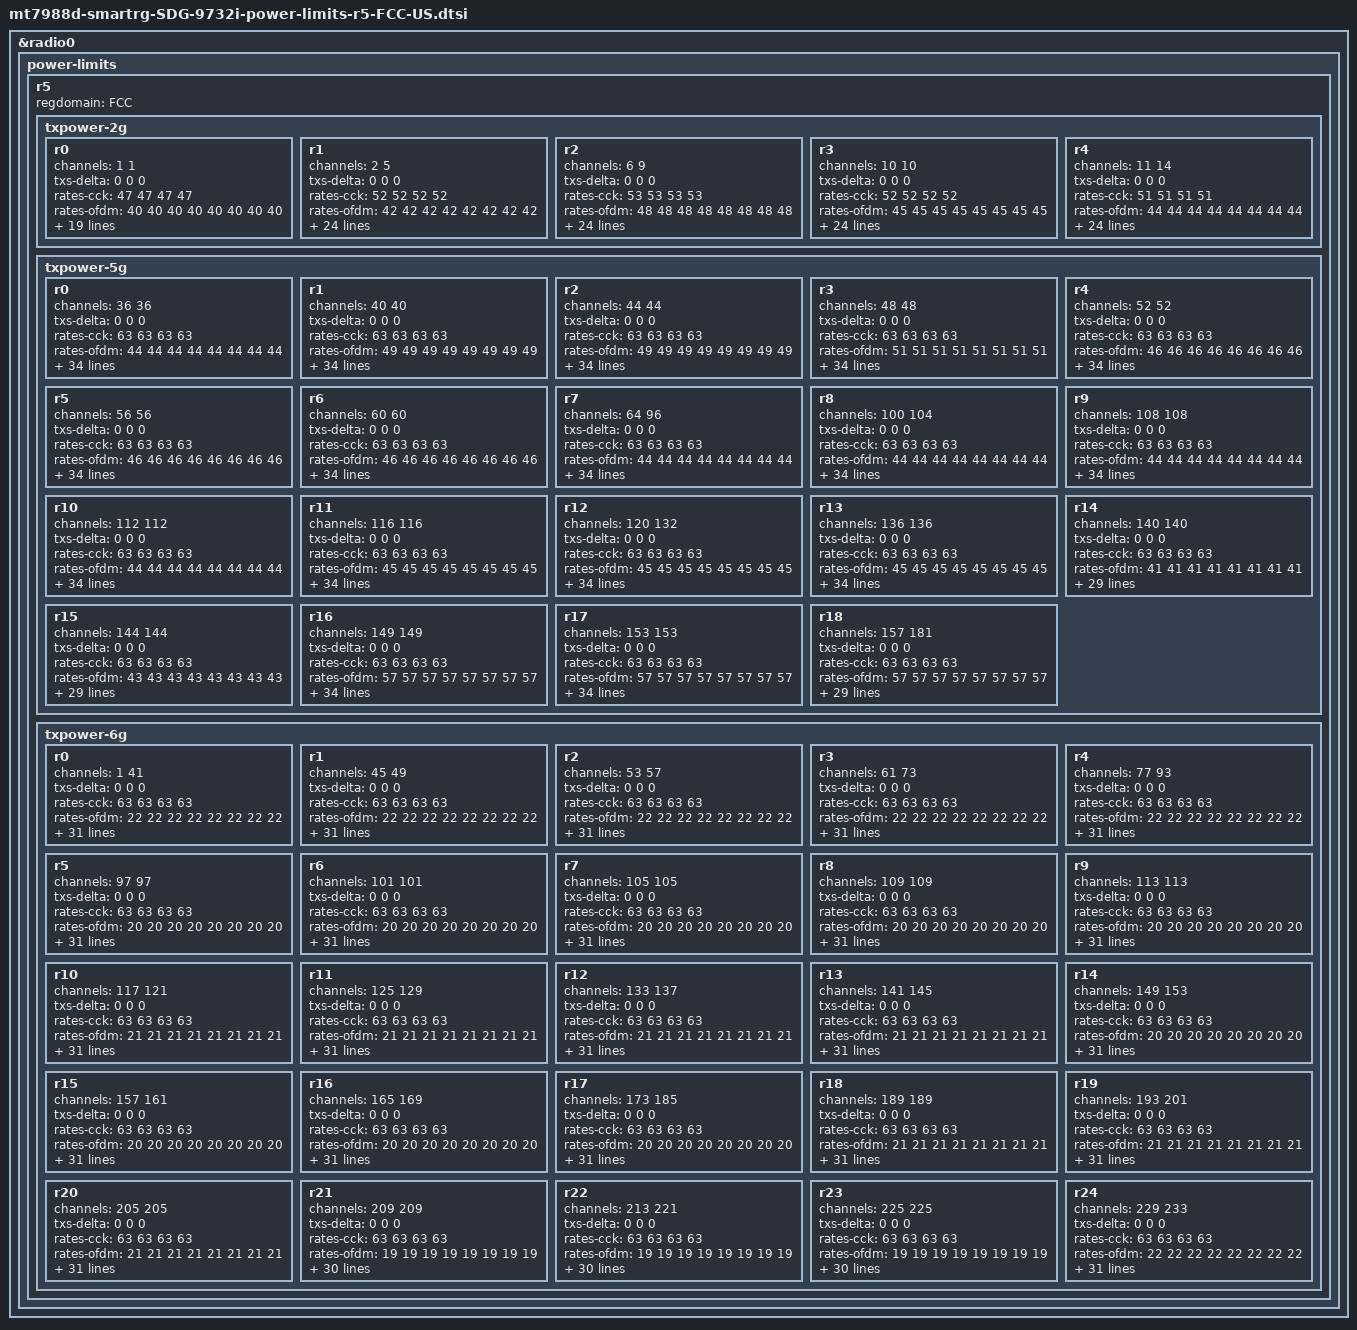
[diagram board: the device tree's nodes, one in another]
// SPDX-License-Identifier: (GPL-2.0 OR MIT)
/*
 * Copyright (C) 2024 SmartRG Inc.
 * Author: Chad Monroe <chad.monroe@smartrg.com>
 */

&radio0 {
	power-limits {
		r5 {
			regdomain = "FCC";

			txpower-2g {
				r0 {
					channels = <1 1>;
					txs-delta = <0 0 0>;
					rates-cck = /bits/ 8 <47 47 47 47>;
					rates-ofdm = /bits/ 8 <40 40 40 40 40 40 40 40>;
					rates-mcs =
					/bits/ 8 <2 39 39 39 39 39 39 39 39 39 39>,
					/bits/ 8 <2 63 63 63 63 63 63 63 63 63 63>;
					rates-ru =
					/bits/ 8 <5 39 39 39 39 39 39 39 39 39 39 39 39>,
					/bits/ 8 <2 63 63 63 63 63 63 63 63 63 63 63 63>;
					rates-eht =
					/bits/ 8 <5 39 39 39 39 39 39 39 39 39 39 39 39 39 39 39 39>,
					/bits/ 8 <3 63 63 63 63 63 63 63 63 63 63 63 63 63 63 63 63>,
					/bits/ 8 <2 39 39 39 39 39 39 39 39 39 39 39 39 39 39 39 39>,
					/bits/ 8 <6 63 63 63 63 63 63 63 63 63 63 63 63 63 63 63 63>;
					paths-cck = /bits/ 8 <47 41 37 35 33>;
					paths-ofdm = /bits/ 8 <40 34 30 28 26>;
					paths-ofdm-bf = /bits/ 8 <28 21 16 12>;
					paths-ru =
					/bits/ 8 <7 39 33 29 27 25 33 29 27 25 29 27 25 27 25 25>,
					/bits/ 8 <9 63 63 63 63 63 63 63 63 63 63 63 63 63 63 63>;
					paths-ru-bf =
					/bits/ 8 <7 39 27 20 15 11 33 26 21 17 29 24 21 27 23 25>,
					/bits/ 8 <9 63 63 63 63 63 63 63 63 63 63 63 63 63 63 63>;
				};
				r1 {
					channels = <2 5>;
					txs-delta = <0 0 0>;
					rates-cck = /bits/ 8 <52 52 52 52>;
					rates-ofdm = /bits/ 8 <42 42 42 42 42 42 42 42>;
					rates-mcs =
					/bits/ 8 <1 42 42 42 42 42 42 42 42 42 42>,
					/bits/ 8 <1 39 39 39 39 39 39 39 39 39 39>,
					/bits/ 8 <2 63 63 63 63 63 63 63 63 63 63>;
					rates-ru =
					/bits/ 8 <4 42 42 42 42 42 42 42 42 42 42 42 42>,
					/bits/ 8 <1 39 39 39 39 39 39 39 39 39 39 39 39>,
					/bits/ 8 <2 63 63 63 63 63 63 63 63 63 63 63 63>;
					rates-eht =
					/bits/ 8 <4 42 42 42 42 42 42 42 42 42 42 42 42 42 42 42 42>,
					/bits/ 8 <1 39 39 39 39 39 39 39 39 39 39 39 39 39 39 39 39>,
					/bits/ 8 <3 63 63 63 63 63 63 63 63 63 63 63 63 63 63 63 63>,
					/bits/ 8 <2 42 42 42 42 42 42 42 42 42 42 42 42 42 42 42 42>,
					/bits/ 8 <6 63 63 63 63 63 63 63 63 63 63 63 63 63 63 63 63>;
					paths-cck = /bits/ 8 <52 46 42 40 38>;
					paths-ofdm = /bits/ 8 <42 36 32 30 28>;
					paths-ofdm-bf = /bits/ 8 <30 23 18 14>;
					paths-ru =
					/bits/ 8 <6 42 36 32 30 28 36 32 30 28 32 30 28 30 28 28>,
					/bits/ 8 <1 39 33 29 27 25 33 29 27 25 29 27 25 27 25 25>,
					/bits/ 8 <9 63 63 63 63 63 63 63 63 63 63 63 63 63 63 63>;
					paths-ru-bf =
					/bits/ 8 <6 42 30 23 18 14 36 29 24 20 32 27 24 30 26 28>,
					/bits/ 8 <1 39 27 20 15 11 33 26 21 17 29 24 21 27 23 25>,
					/bits/ 8 <9 63 63 63 63 63 63 63 63 63 63 63 63 63 63 63>;
				};
				r2 {
					channels = <6 9>;
					txs-delta = <0 0 0>;
					rates-cck = /bits/ 8 <53 53 53 53>;
					rates-ofdm = /bits/ 8 <48 48 48 48 48 48 48 48>;
					rates-mcs =
					/bits/ 8 <1 46 46 46 46 46 46 46 46 46 46>,
					/bits/ 8 <1 41 41 41 41 41 41 41 41 41 41>,
					/bits/ 8 <2 63 63 63 63 63 63 63 63 63 63>;
					rates-ru =
					/bits/ 8 <4 46 46 46 46 46 46 46 46 46 46 46 46>,
					/bits/ 8 <1 41 41 41 41 41 41 41 41 41 41 41 41>,
					/bits/ 8 <2 63 63 63 63 63 63 63 63 63 63 63 63>;
					rates-eht =
					/bits/ 8 <4 46 46 46 46 46 46 46 46 46 46 46 46 46 46 46 46>,
					/bits/ 8 <1 41 41 41 41 41 41 41 41 41 41 41 41 41 41 41 41>,
					/bits/ 8 <3 63 63 63 63 63 63 63 63 63 63 63 63 63 63 63 63>,
					/bits/ 8 <2 46 46 46 46 46 46 46 46 46 46 46 46 46 46 46 46>,
					/bits/ 8 <6 63 63 63 63 63 63 63 63 63 63 63 63 63 63 63 63>;
					paths-cck = /bits/ 8 <53 47 43 41 39>;
					paths-ofdm = /bits/ 8 <48 42 38 36 34>;
					paths-ofdm-bf = /bits/ 8 <36 29 24 20>;
					paths-ru =
					/bits/ 8 <6 46 40 36 34 32 40 36 34 32 36 34 32 34 32 32>,
					/bits/ 8 <1 41 35 31 29 27 35 31 29 27 31 29 27 29 27 27>,
					/bits/ 8 <9 63 63 63 63 63 63 63 63 63 63 63 63 63 63 63>;
					paths-ru-bf =
					/bits/ 8 <6 46 34 27 22 18 40 33 28 24 36 31 28 34 30 32>,
					/bits/ 8 <1 41 29 22 17 13 35 28 23 19 31 26 23 29 25 27>,
					/bits/ 8 <9 63 63 63 63 63 63 63 63 63 63 63 63 63 63 63>;
				};
				r3 {
					channels = <10 10>;
					txs-delta = <0 0 0>;
					rates-cck = /bits/ 8 <52 52 52 52>;
					rates-ofdm = /bits/ 8 <45 45 45 45 45 45 45 45>;
					rates-mcs =
					/bits/ 8 <1 44 44 44 44 44 44 44 44 44 44>,
					/bits/ 8 <1 41 41 41 41 41 41 41 41 41 41>,
					/bits/ 8 <2 63 63 63 63 63 63 63 63 63 63>;
					rates-ru =
					/bits/ 8 <4 44 44 44 44 44 44 44 44 44 44 44 44>,
					/bits/ 8 <1 41 41 41 41 41 41 41 41 41 41 41 41>,
					/bits/ 8 <2 63 63 63 63 63 63 63 63 63 63 63 63>;
					rates-eht =
					/bits/ 8 <4 44 44 44 44 44 44 44 44 44 44 44 44 44 44 44 44>,
					/bits/ 8 <1 41 41 41 41 41 41 41 41 41 41 41 41 41 41 41 41>,
					/bits/ 8 <3 63 63 63 63 63 63 63 63 63 63 63 63 63 63 63 63>,
					/bits/ 8 <2 44 44 44 44 44 44 44 44 44 44 44 44 44 44 44 44>,
					/bits/ 8 <6 63 63 63 63 63 63 63 63 63 63 63 63 63 63 63 63>;
					paths-cck = /bits/ 8 <52 46 42 40 38>;
					paths-ofdm = /bits/ 8 <45 39 35 33 31>;
					paths-ofdm-bf = /bits/ 8 <33 26 21 17>;
					paths-ru =
					/bits/ 8 <6 44 38 34 32 30 38 34 32 30 34 32 30 32 30 30>,
					/bits/ 8 <1 41 35 31 29 27 35 31 29 27 31 29 27 29 27 27>,
					/bits/ 8 <9 63 63 63 63 63 63 63 63 63 63 63 63 63 63 63>;
					paths-ru-bf =
					/bits/ 8 <6 44 32 25 20 16 38 31 26 22 34 29 26 32 28 30>,
					/bits/ 8 <1 41 29 22 17 13 35 28 23 19 31 26 23 29 25 27>,
					/bits/ 8 <9 63 63 63 63 63 63 63 63 63 63 63 63 63 63 63>;
				};
				r4 {
					channels = <11 14>;
					txs-delta = <0 0 0>;
					rates-cck = /bits/ 8 <51 51 51 51>;
					rates-ofdm = /bits/ 8 <44 44 44 44 44 44 44 44>;
					rates-mcs =
					/bits/ 8 <1 42 42 42 42 42 42 42 42 42 42>,
					/bits/ 8 <1 41 41 41 41 41 41 41 41 41 41>,
					/bits/ 8 <2 63 63 63 63 63 63 63 63 63 63>;
					rates-ru =
					/bits/ 8 <4 42 42 42 42 42 42 42 42 42 42 42 42>,
					/bits/ 8 <1 41 41 41 41 41 41 41 41 41 41 41 41>,
					/bits/ 8 <2 63 63 63 63 63 63 63 63 63 63 63 63>;
					rates-eht =
					/bits/ 8 <4 42 42 42 42 42 42 42 42 42 42 42 42 42 42 42 42>,
					/bits/ 8 <1 41 41 41 41 41 41 41 41 41 41 41 41 41 41 41 41>,
					/bits/ 8 <3 63 63 63 63 63 63 63 63 63 63 63 63 63 63 63 63>,
					/bits/ 8 <2 42 42 42 42 42 42 42 42 42 42 42 42 42 42 42 42>,
					/bits/ 8 <6 63 63 63 63 63 63 63 63 63 63 63 63 63 63 63 63>;
					paths-cck = /bits/ 8 <51 45 41 39 37>;
					paths-ofdm = /bits/ 8 <44 38 34 32 30>;
					paths-ofdm-bf = /bits/ 8 <32 25 20 16>;
					paths-ru =
					/bits/ 8 <6 42 36 32 30 28 36 32 30 28 32 30 28 30 28 28>,
					/bits/ 8 <1 41 35 31 29 27 35 31 29 27 31 29 27 29 27 27>,
					/bits/ 8 <9 63 63 63 63 63 63 63 63 63 63 63 63 63 63 63>;
					paths-ru-bf =
					/bits/ 8 <6 42 30 23 18 14 36 29 24 20 32 27 24 30 26 28>,
					/bits/ 8 <1 41 29 22 17 13 35 28 23 19 31 26 23 29 25 27>,
					/bits/ 8 <9 63 63 63 63 63 63 63 63 63 63 63 63 63 63 63>;
				};
			};
			txpower-5g {
				r0 {
					channels = <36 36>;
					txs-delta = <0 0 0>;
					rates-cck = /bits/ 8 <63 63 63 63>;
					rates-ofdm = /bits/ 8 <44 44 44 44 44 44 44 44>;
					rates-mcs =
					/bits/ 8 <1 42 42 42 42 42 42 42 42 42 42>,
					/bits/ 8 <1 38 38 38 38 38 38 38 38 38 38>,
					/bits/ 8 <1 32 32 32 32 32 32 32 32 32 32>,
					/bits/ 8 <1 28 28 28 28 28 28 28 28 28 28>;
					rates-ru =
					/bits/ 8 <4 42 42 42 42 42 42 42 42 42 42 42 42>,
					/bits/ 8 <1 38 38 38 38 38 38 38 38 38 38 38 38>,
					/bits/ 8 <1 32 32 32 32 32 32 32 32 32 32 32 32>,
					/bits/ 8 <1 28 28 28 28 28 28 28 28 28 28 28 28>;
					rates-eht =
					/bits/ 8 <4 42 42 42 42 42 42 42 42 42 42 42 42 42 42 42 42>,
					/bits/ 8 <1 38 38 38 38 38 38 38 38 38 38 38 38 38 38 38 38>,
					/bits/ 8 <1 32 32 32 32 32 32 32 32 32 32 32 32 32 32 32 32>,
					/bits/ 8 <1 28 28 28 28 28 28 28 28 28 28 28 28 28 28 28 28>,
					/bits/ 8 <1 63 63 63 63 63 63 63 63 63 63 63 63 63 63 63 63>,
					/bits/ 8 <2 42 42 42 42 42 42 42 42 42 42 42 42 42 42 42 42>,
					/bits/ 8 <1 32 32 32 32 32 32 32 32 32 32 32 32 32 32 32 32>,
					/bits/ 8 <2 28 28 28 28 28 28 28 28 28 28 28 28 28 28 28 28>,
					/bits/ 8 <3 63 63 63 63 63 63 63 63 63 63 63 63 63 63 63 63>;
					paths-cck = /bits/ 8 <63 63 63 63 63>;
					paths-ofdm = /bits/ 8 <44 38 34 32 30>;
					paths-ofdm-bf = /bits/ 8 <32 25 20 16>;
					paths-ru =
					/bits/ 8 <6 42 36 32 30 28 36 32 30 28 32 30 28 30 28 28>,
					/bits/ 8 <1 38 32 28 26 24 32 28 26 24 28 26 24 26 24 24>,
					/bits/ 8 <2 32 26 22 20 18 26 22 20 18 22 20 18 20 18 18>,
					/bits/ 8 <3 28 22 18 16 14 22 18 16 14 18 16 14 16 14 14>,
					/bits/ 8 <4 63 63 63 63 63 63 63 63 63 63 63 63 63 63 63>;
					paths-ru-bf =
					/bits/ 8 <6 42 30 23 18 14 36 29 24 20 32 27 24 30 26 28>,
					/bits/ 8 <1 38 26 19 14 10 32 25 20 16 28 23 20 26 22 24>,
					/bits/ 8 <2 32 20 13 8 4 26 19 14 10 22 17 14 20 16 18>,
					/bits/ 8 <3 28 16 9 4 0 22 15 10 6 18 13 10 16 12 14>,
					/bits/ 8 <4 63 63 63 63 63 63 63 63 63 63 63 63 63 63 63>;
				};
				r1 {
					channels = <40 40>;
					txs-delta = <0 0 0>;
					rates-cck = /bits/ 8 <63 63 63 63>;
					rates-ofdm = /bits/ 8 <49 49 49 49 49 49 49 49>;
					rates-mcs =
					/bits/ 8 <1 47 47 47 47 47 47 47 47 47 47>,
					/bits/ 8 <1 38 38 38 38 38 38 38 38 38 38>,
					/bits/ 8 <1 32 32 32 32 32 32 32 32 32 32>,
					/bits/ 8 <1 28 28 28 28 28 28 28 28 28 28>;
					rates-ru =
					/bits/ 8 <4 47 47 47 47 47 47 47 47 47 47 47 47>,
					/bits/ 8 <1 38 38 38 38 38 38 38 38 38 38 38 38>,
					/bits/ 8 <1 32 32 32 32 32 32 32 32 32 32 32 32>,
					/bits/ 8 <1 28 28 28 28 28 28 28 28 28 28 28 28>;
					rates-eht =
					/bits/ 8 <4 47 47 47 47 47 47 47 47 47 47 47 47 47 47 47 47>,
					/bits/ 8 <1 38 38 38 38 38 38 38 38 38 38 38 38 38 38 38 38>,
					/bits/ 8 <1 32 32 32 32 32 32 32 32 32 32 32 32 32 32 32 32>,
					/bits/ 8 <1 28 28 28 28 28 28 28 28 28 28 28 28 28 28 28 28>,
					/bits/ 8 <1 63 63 63 63 63 63 63 63 63 63 63 63 63 63 63 63>,
					/bits/ 8 <2 47 47 47 47 47 47 47 47 47 47 47 47 47 47 47 47>,
					/bits/ 8 <1 32 32 32 32 32 32 32 32 32 32 32 32 32 32 32 32>,
					/bits/ 8 <2 28 28 28 28 28 28 28 28 28 28 28 28 28 28 28 28>,
					/bits/ 8 <3 63 63 63 63 63 63 63 63 63 63 63 63 63 63 63 63>;
					paths-cck = /bits/ 8 <63 63 63 63 63>;
					paths-ofdm = /bits/ 8 <49 43 39 37 35>;
					paths-ofdm-bf = /bits/ 8 <37 30 25 21>;
					paths-ru =
					/bits/ 8 <6 47 41 37 35 33 41 37 35 33 37 35 33 35 33 33>,
					/bits/ 8 <1 38 32 28 26 24 32 28 26 24 28 26 24 26 24 24>,
					/bits/ 8 <2 32 26 22 20 18 26 22 20 18 22 20 18 20 18 18>,
					/bits/ 8 <3 28 22 18 16 14 22 18 16 14 18 16 14 16 14 14>,
					/bits/ 8 <4 63 63 63 63 63 63 63 63 63 63 63 63 63 63 63>;
					paths-ru-bf =
					/bits/ 8 <6 47 35 28 23 19 41 34 29 25 37 32 29 35 31 33>,
					/bits/ 8 <1 38 26 19 14 10 32 25 20 16 28 23 20 26 22 24>,
					/bits/ 8 <2 32 20 13 8 4 26 19 14 10 22 17 14 20 16 18>,
					/bits/ 8 <3 28 16 9 4 0 22 15 10 6 18 13 10 16 12 14>,
					/bits/ 8 <4 63 63 63 63 63 63 63 63 63 63 63 63 63 63 63>;
				};
				r2 {
					channels = <44 44>;
					txs-delta = <0 0 0>;
					rates-cck = /bits/ 8 <63 63 63 63>;
					rates-ofdm = /bits/ 8 <49 49 49 49 49 49 49 49>;
					rates-mcs =
					/bits/ 8 <1 47 47 47 47 47 47 47 47 47 47>,
					/bits/ 8 <1 44 44 44 44 44 44 44 44 44 44>,
					/bits/ 8 <1 32 32 32 32 32 32 32 32 32 32>,
					/bits/ 8 <1 28 28 28 28 28 28 28 28 28 28>;
					rates-ru =
					/bits/ 8 <4 47 47 47 47 47 47 47 47 47 47 47 47>,
					/bits/ 8 <1 44 44 44 44 44 44 44 44 44 44 44 44>,
					/bits/ 8 <1 32 32 32 32 32 32 32 32 32 32 32 32>,
					/bits/ 8 <1 28 28 28 28 28 28 28 28 28 28 28 28>;
					rates-eht =
					/bits/ 8 <4 47 47 47 47 47 47 47 47 47 47 47 47 47 47 47 47>,
					/bits/ 8 <1 44 44 44 44 44 44 44 44 44 44 44 44 44 44 44 44>,
					/bits/ 8 <1 32 32 32 32 32 32 32 32 32 32 32 32 32 32 32 32>,
					/bits/ 8 <1 28 28 28 28 28 28 28 28 28 28 28 28 28 28 28 28>,
					/bits/ 8 <1 63 63 63 63 63 63 63 63 63 63 63 63 63 63 63 63>,
					/bits/ 8 <2 47 47 47 47 47 47 47 47 47 47 47 47 47 47 47 47>,
					/bits/ 8 <1 32 32 32 32 32 32 32 32 32 32 32 32 32 32 32 32>,
					/bits/ 8 <2 28 28 28 28 28 28 28 28 28 28 28 28 28 28 28 28>,
					/bits/ 8 <3 63 63 63 63 63 63 63 63 63 63 63 63 63 63 63 63>;
					paths-cck = /bits/ 8 <63 63 63 63 63>;
					paths-ofdm = /bits/ 8 <49 43 39 37 35>;
					paths-ofdm-bf = /bits/ 8 <37 30 25 21>;
					paths-ru =
					/bits/ 8 <6 47 41 37 35 33 41 37 35 33 37 35 33 35 33 33>,
					/bits/ 8 <1 44 38 34 32 30 38 34 32 30 34 32 30 32 30 30>,
					/bits/ 8 <2 32 26 22 20 18 26 22 20 18 22 20 18 20 18 18>,
					/bits/ 8 <3 28 22 18 16 14 22 18 16 14 18 16 14 16 14 14>,
					/bits/ 8 <4 63 63 63 63 63 63 63 63 63 63 63 63 63 63 63>;
					paths-ru-bf =
					/bits/ 8 <6 47 35 28 23 19 41 34 29 25 37 32 29 35 31 33>,
					/bits/ 8 <1 44 32 25 20 16 38 31 26 22 34 29 26 32 28 30>,
					/bits/ 8 <2 32 20 13 8 4 26 19 14 10 22 17 14 20 16 18>,
					/bits/ 8 <3 28 16 9 4 0 22 15 10 6 18 13 10 16 12 14>,
					/bits/ 8 <4 63 63 63 63 63 63 63 63 63 63 63 63 63 63 63>;
				};
				r3 {
					channels = <48 48>;
					txs-delta = <0 0 0>;
					rates-cck = /bits/ 8 <63 63 63 63>;
					rates-ofdm = /bits/ 8 <51 51 51 51 51 51 51 51>;
					rates-mcs =
					/bits/ 8 <1 50 50 50 50 50 50 50 50 50 50>,
					/bits/ 8 <1 44 44 44 44 44 44 44 44 44 44>,
					/bits/ 8 <1 32 32 32 32 32 32 32 32 32 32>,
					/bits/ 8 <1 28 28 28 28 28 28 28 28 28 28>;
					rates-ru =
					/bits/ 8 <4 50 50 50 50 50 50 50 50 50 50 50 50>,
					/bits/ 8 <1 44 44 44 44 44 44 44 44 44 44 44 44>,
					/bits/ 8 <1 32 32 32 32 32 32 32 32 32 32 32 32>,
					/bits/ 8 <1 28 28 28 28 28 28 28 28 28 28 28 28>;
					rates-eht =
					/bits/ 8 <4 50 50 50 50 50 50 50 50 50 50 50 50 50 50 50 50>,
					/bits/ 8 <1 44 44 44 44 44 44 44 44 44 44 44 44 44 44 44 44>,
					/bits/ 8 <1 32 32 32 32 32 32 32 32 32 32 32 32 32 32 32 32>,
					/bits/ 8 <1 28 28 28 28 28 28 28 28 28 28 28 28 28 28 28 28>,
					/bits/ 8 <1 63 63 63 63 63 63 63 63 63 63 63 63 63 63 63 63>,
					/bits/ 8 <2 50 50 50 50 50 50 50 50 50 50 50 50 50 50 50 50>,
					/bits/ 8 <1 32 32 32 32 32 32 32 32 32 32 32 32 32 32 32 32>,
					/bits/ 8 <2 28 28 28 28 28 28 28 28 28 28 28 28 28 28 28 28>,
					/bits/ 8 <3 63 63 63 63 63 63 63 63 63 63 63 63 63 63 63 63>;
					paths-cck = /bits/ 8 <63 63 63 63 63>;
					paths-ofdm = /bits/ 8 <51 45 41 39 37>;
					paths-ofdm-bf = /bits/ 8 <39 32 27 23>;
					paths-ru =
					/bits/ 8 <6 50 44 40 38 36 44 40 38 36 40 38 36 38 36 36>,
					/bits/ 8 <1 44 38 34 32 30 38 34 32 30 34 32 30 32 30 30>,
					/bits/ 8 <2 32 26 22 20 18 26 22 20 18 22 20 18 20 18 18>,
					/bits/ 8 <3 28 22 18 16 14 22 18 16 14 18 16 14 16 14 14>,
					/bits/ 8 <4 63 63 63 63 63 63 63 63 63 63 63 63 63 63 63>;
					paths-ru-bf =
					/bits/ 8 <6 50 38 31 26 22 44 37 32 28 40 35 32 38 34 36>,
					/bits/ 8 <1 44 32 25 20 16 38 31 26 22 34 29 26 32 28 30>,
					/bits/ 8 <2 32 20 13 8 4 26 19 14 10 22 17 14 20 16 18>,
					/bits/ 8 <3 28 16 9 4 0 22 15 10 6 18 13 10 16 12 14>,
					/bits/ 8 <4 63 63 63 63 63 63 63 63 63 63 63 63 63 63 63>;
				};
				r4 {
					channels = <52 52>;
					txs-delta = <0 0 0>;
					rates-cck = /bits/ 8 <63 63 63 63>;
					rates-ofdm = /bits/ 8 <46 46 46 46 46 46 46 46>;
					rates-mcs =
					/bits/ 8 <1 47 47 47 47 47 47 47 47 47 47>,
					/bits/ 8 <1 43 43 43 43 43 43 43 43 43 43>,
					/bits/ 8 <1 32 32 32 32 32 32 32 32 32 32>,
					/bits/ 8 <1 28 28 28 28 28 28 28 28 28 28>;
					rates-ru =
					/bits/ 8 <4 47 47 47 47 47 47 47 47 47 47 47 47>,
					/bits/ 8 <1 43 43 43 43 43 43 43 43 43 43 43 43>,
					/bits/ 8 <1 32 32 32 32 32 32 32 32 32 32 32 32>,
					/bits/ 8 <1 28 28 28 28 28 28 28 28 28 28 28 28>;
					rates-eht =
					/bits/ 8 <4 47 47 47 47 47 47 47 47 47 47 47 47 47 47 47 47>,
					/bits/ 8 <1 43 43 43 43 43 43 43 43 43 43 43 43 43 43 43 43>,
					/bits/ 8 <1 32 32 32 32 32 32 32 32 32 32 32 32 32 32 32 32>,
					/bits/ 8 <1 28 28 28 28 28 28 28 28 28 28 28 28 28 28 28 28>,
					/bits/ 8 <1 63 63 63 63 63 63 63 63 63 63 63 63 63 63 63 63>,
					/bits/ 8 <2 47 47 47 47 47 47 47 47 47 47 47 47 47 47 47 47>,
					/bits/ 8 <1 32 32 32 32 32 32 32 32 32 32 32 32 32 32 32 32>,
					/bits/ 8 <2 28 28 28 28 28 28 28 28 28 28 28 28 28 28 28 28>,
					/bits/ 8 <3 63 63 63 63 63 63 63 63 63 63 63 63 63 63 63 63>;
					paths-cck = /bits/ 8 <63 63 63 63 63>;
					paths-ofdm = /bits/ 8 <46 40 36 34 32>;
					paths-ofdm-bf = /bits/ 8 <34 27 22 18>;
					paths-ru =
					/bits/ 8 <6 47 41 37 35 33 41 37 35 33 37 35 33 35 33 33>,
					/bits/ 8 <1 43 37 33 31 29 37 33 31 29 33 31 29 31 29 29>,
					/bits/ 8 <2 32 26 22 20 18 26 22 20 18 22 20 18 20 18 18>,
					/bits/ 8 <3 28 22 18 16 14 22 18 16 14 18 16 14 16 14 14>,
					/bits/ 8 <4 63 63 63 63 63 63 63 63 63 63 63 63 63 63 63>;
					paths-ru-bf =
					/bits/ 8 <6 47 35 28 23 19 41 34 29 25 37 32 29 35 31 33>,
					/bits/ 8 <1 43 31 24 19 15 37 30 25 21 33 28 25 31 27 29>,
					/bits/ 8 <2 32 20 13 8 4 26 19 14 10 22 17 14 20 16 18>,
					/bits/ 8 <3 28 16 9 4 0 22 15 10 6 18 13 10 16 12 14>,
					/bits/ 8 <4 63 63 63 63 63 63 63 63 63 63 63 63 63 63 63>;
				};
				r5 {
					channels = <56 56>;
					txs-delta = <0 0 0>;
					rates-cck = /bits/ 8 <63 63 63 63>;
					rates-ofdm = /bits/ 8 <46 46 46 46 46 46 46 46>;
					rates-mcs =
					/bits/ 8 <1 47 47 47 47 47 47 47 47 47 47>,
					/bits/ 8 <1 43 43 43 43 43 43 43 43 43 43>,
					/bits/ 8 <1 37 37 37 37 37 37 37 37 37 37>,
					/bits/ 8 <1 28 28 28 28 28 28 28 28 28 28>;
					rates-ru =
					/bits/ 8 <4 47 47 47 47 47 47 47 47 47 47 47 47>,
					/bits/ 8 <1 43 43 43 43 43 43 43 43 43 43 43 43>,
					/bits/ 8 <1 37 37 37 37 37 37 37 37 37 37 37 37>,
					/bits/ 8 <1 28 28 28 28 28 28 28 28 28 28 28 28>;
					rates-eht =
					/bits/ 8 <4 47 47 47 47 47 47 47 47 47 47 47 47 47 47 47 47>,
					/bits/ 8 <1 43 43 43 43 43 43 43 43 43 43 43 43 43 43 43 43>,
					/bits/ 8 <1 37 37 37 37 37 37 37 37 37 37 37 37 37 37 37 37>,
					/bits/ 8 <1 28 28 28 28 28 28 28 28 28 28 28 28 28 28 28 28>,
					/bits/ 8 <1 63 63 63 63 63 63 63 63 63 63 63 63 63 63 63 63>,
					/bits/ 8 <2 47 47 47 47 47 47 47 47 47 47 47 47 47 47 47 47>,
					/bits/ 8 <1 37 37 37 37 37 37 37 37 37 37 37 37 37 37 37 37>,
					/bits/ 8 <2 28 28 28 28 28 28 28 28 28 28 28 28 28 28 28 28>,
					/bits/ 8 <3 63 63 63 63 63 63 63 63 63 63 63 63 63 63 63 63>;
					paths-cck = /bits/ 8 <63 63 63 63 63>;
					paths-ofdm = /bits/ 8 <46 40 36 34 32>;
					paths-ofdm-bf = /bits/ 8 <34 27 22 18>;
					paths-ru =
					/bits/ 8 <6 47 41 37 35 33 41 37 35 33 37 35 33 35 33 33>,
					/bits/ 8 <1 43 37 33 31 29 37 33 31 29 33 31 29 31 29 29>,
					/bits/ 8 <2 37 31 27 25 23 31 27 25 23 27 25 23 25 23 23>,
					/bits/ 8 <3 28 22 18 16 14 22 18 16 14 18 16 14 16 14 14>,
					/bits/ 8 <4 63 63 63 63 63 63 63 63 63 63 63 63 63 63 63>;
					paths-ru-bf =
					/bits/ 8 <6 47 35 28 23 19 41 34 29 25 37 32 29 35 31 33>,
					/bits/ 8 <1 43 31 24 19 15 37 30 25 21 33 28 25 31 27 29>,
					/bits/ 8 <2 37 25 18 13 9 31 24 19 15 27 22 19 25 21 23>,
					/bits/ 8 <3 28 16 9 4 0 22 15 10 6 18 13 10 16 12 14>,
					/bits/ 8 <4 63 63 63 63 63 63 63 63 63 63 63 63 63 63 63>;
				};
				r6 {
					channels = <60 60>;
					txs-delta = <0 0 0>;
					rates-cck = /bits/ 8 <63 63 63 63>;
					rates-ofdm = /bits/ 8 <46 46 46 46 46 46 46 46>;
					rates-mcs =
					/bits/ 8 <1 46 46 46 46 46 46 46 46 46 46>,
					/bits/ 8 <1 40 40 40 40 40 40 40 40 40 40>,
					/bits/ 8 <1 37 37 37 37 37 37 37 37 37 37>,
					/bits/ 8 <1 28 28 28 28 28 28 28 28 28 28>;
					rates-ru =
					/bits/ 8 <4 46 46 46 46 46 46 46 46 46 46 46 46>,
					/bits/ 8 <1 40 40 40 40 40 40 40 40 40 40 40 40>,
					/bits/ 8 <1 37 37 37 37 37 37 37 37 37 37 37 37>,
					/bits/ 8 <1 28 28 28 28 28 28 28 28 28 28 28 28>;
					rates-eht =
					/bits/ 8 <4 46 46 46 46 46 46 46 46 46 46 46 46 46 46 46 46>,
					/bits/ 8 <1 40 40 40 40 40 40 40 40 40 40 40 40 40 40 40 40>,
					/bits/ 8 <1 37 37 37 37 37 37 37 37 37 37 37 37 37 37 37 37>,
					/bits/ 8 <1 28 28 28 28 28 28 28 28 28 28 28 28 28 28 28 28>,
					/bits/ 8 <1 63 63 63 63 63 63 63 63 63 63 63 63 63 63 63 63>,
					/bits/ 8 <2 46 46 46 46 46 46 46 46 46 46 46 46 46 46 46 46>,
					/bits/ 8 <1 37 37 37 37 37 37 37 37 37 37 37 37 37 37 37 37>,
					/bits/ 8 <2 28 28 28 28 28 28 28 28 28 28 28 28 28 28 28 28>,
					/bits/ 8 <3 63 63 63 63 63 63 63 63 63 63 63 63 63 63 63 63>;
					paths-cck = /bits/ 8 <63 63 63 63 63>;
					paths-ofdm = /bits/ 8 <46 40 36 34 32>;
					paths-ofdm-bf = /bits/ 8 <34 27 22 18>;
					paths-ru =
					/bits/ 8 <6 46 40 36 34 32 40 36 34 32 36 34 32 34 32 32>,
					/bits/ 8 <1 40 34 30 28 26 34 30 28 26 30 28 26 28 26 26>,
					/bits/ 8 <2 37 31 27 25 23 31 27 25 23 27 25 23 25 23 23>,
					/bits/ 8 <3 28 22 18 16 14 22 18 16 14 18 16 14 16 14 14>,
					/bits/ 8 <4 63 63 63 63 63 63 63 63 63 63 63 63 63 63 63>;
					paths-ru-bf =
					/bits/ 8 <6 46 34 27 22 18 40 33 28 24 36 31 28 34 30 32>,
					/bits/ 8 <1 40 28 21 16 12 34 27 22 18 30 25 22 28 24 26>,
					/bits/ 8 <2 37 25 18 13 9 31 24 19 15 27 22 19 25 21 23>,
					/bits/ 8 <3 28 16 9 4 0 22 15 10 6 18 13 10 16 12 14>,
					/bits/ 8 <4 63 63 63 63 63 63 63 63 63 63 63 63 63 63 63>;
				};
				r7 {
					channels = <64 96>;
					txs-delta = <0 0 0>;
					rates-cck = /bits/ 8 <63 63 63 63>;
					rates-ofdm = /bits/ 8 <44 44 44 44 44 44 44 44>;
					rates-mcs =
					/bits/ 8 <1 43 43 43 43 43 43 43 43 43 43>,
					/bits/ 8 <1 40 40 40 40 40 40 40 40 40 40>,
					/bits/ 8 <1 37 37 37 37 37 37 37 37 37 37>,
					/bits/ 8 <1 28 28 28 28 28 28 28 28 28 28>;
					rates-ru =
					/bits/ 8 <4 43 43 43 43 43 43 43 43 43 43 43 43>,
					/bits/ 8 <1 40 40 40 40 40 40 40 40 40 40 40 40>,
					/bits/ 8 <1 37 37 37 37 37 37 37 37 37 37 37 37>,
					/bits/ 8 <1 28 28 28 28 28 28 28 28 28 28 28 28>;
					rates-eht =
					/bits/ 8 <4 43 43 43 43 43 43 43 43 43 43 43 43 43 43 43 43>,
					/bits/ 8 <1 40 40 40 40 40 40 40 40 40 40 40 40 40 40 40 40>,
					/bits/ 8 <1 37 37 37 37 37 37 37 37 37 37 37 37 37 37 37 37>,
					/bits/ 8 <1 28 28 28 28 28 28 28 28 28 28 28 28 28 28 28 28>,
					/bits/ 8 <1 63 63 63 63 63 63 63 63 63 63 63 63 63 63 63 63>,
					/bits/ 8 <2 43 43 43 43 43 43 43 43 43 43 43 43 43 43 43 43>,
					/bits/ 8 <1 37 37 37 37 37 37 37 37 37 37 37 37 37 37 37 37>,
					/bits/ 8 <2 28 28 28 28 28 28 28 28 28 28 28 28 28 28 28 28>,
					/bits/ 8 <3 63 63 63 63 63 63 63 63 63 63 63 63 63 63 63 63>;
					paths-cck = /bits/ 8 <63 63 63 63 63>;
					paths-ofdm = /bits/ 8 <44 38 34 32 30>;
					paths-ofdm-bf = /bits/ 8 <32 25 20 16>;
					paths-ru =
					/bits/ 8 <6 43 37 33 31 29 37 33 31 29 33 31 29 31 29 29>,
					/bits/ 8 <1 40 34 30 28 26 34 30 28 26 30 28 26 28 26 26>,
					/bits/ 8 <2 37 31 27 25 23 31 27 25 23 27 25 23 25 23 23>,
					/bits/ 8 <3 28 22 18 16 14 22 18 16 14 18 16 14 16 14 14>,
					/bits/ 8 <4 63 63 63 63 63 63 63 63 63 63 63 63 63 63 63>;
					paths-ru-bf =
					/bits/ 8 <6 43 31 24 19 15 37 30 25 21 33 28 25 31 27 29>,
					/bits/ 8 <1 40 28 21 16 12 34 27 22 18 30 25 22 28 24 26>,
					/bits/ 8 <2 37 25 18 13 9 31 24 19 15 27 22 19 25 21 23>,
					/bits/ 8 <3 28 16 9 4 0 22 15 10 6 18 13 10 16 12 14>,
					/bits/ 8 <4 63 63 63 63 63 63 63 63 63 63 63 63 63 63 63>;
				};
				r8 {
					channels = <100 104>;
					txs-delta = <0 0 0>;
					rates-cck = /bits/ 8 <63 63 63 63>;
					rates-ofdm = /bits/ 8 <44 44 44 44 44 44 44 44>;
					rates-mcs =
					/bits/ 8 <1 43 43 43 43 43 43 43 43 43 43>,
					/bits/ 8 <1 41 41 41 41 41 41 41 41 41 41>,
					/bits/ 8 <1 37 37 37 37 37 37 37 37 37 37>,
					/bits/ 8 <1 28 28 28 28 28 28 28 28 28 28>;
					rates-ru =
					/bits/ 8 <4 43 43 43 43 43 43 43 43 43 43 43 43>,
					/bits/ 8 <1 41 41 41 41 41 41 41 41 41 41 41 41>,
					/bits/ 8 <1 37 37 37 37 37 37 37 37 37 37 37 37>,
					/bits/ 8 <1 28 28 28 28 28 28 28 28 28 28 28 28>;
					rates-eht =
					/bits/ 8 <4 43 43 43 43 43 43 43 43 43 43 43 43 43 43 43 43>,
					/bits/ 8 <1 41 41 41 41 41 41 41 41 41 41 41 41 41 41 41 41>,
					/bits/ 8 <1 37 37 37 37 37 37 37 37 37 37 37 37 37 37 37 37>,
					/bits/ 8 <1 28 28 28 28 28 28 28 28 28 28 28 28 28 28 28 28>,
					/bits/ 8 <1 63 63 63 63 63 63 63 63 63 63 63 63 63 63 63 63>,
					/bits/ 8 <2 43 43 43 43 43 43 43 43 43 43 43 43 43 43 43 43>,
					/bits/ 8 <1 37 37 37 37 37 37 37 37 37 37 37 37 37 37 37 37>,
					/bits/ 8 <2 28 28 28 28 28 28 28 28 28 28 28 28 28 28 28 28>,
					/bits/ 8 <3 63 63 63 63 63 63 63 63 63 63 63 63 63 63 63 63>;
					paths-cck = /bits/ 8 <63 63 63 63 63>;
					paths-ofdm = /bits/ 8 <44 38 34 32 30>;
					paths-ofdm-bf = /bits/ 8 <32 25 20 16>;
					paths-ru =
					/bits/ 8 <6 43 37 33 31 29 37 33 31 29 33 31 29 31 29 29>,
					/bits/ 8 <1 41 35 31 29 27 35 31 29 27 31 29 27 29 27 27>,
					/bits/ 8 <2 37 31 27 25 23 31 27 25 23 27 25 23 25 23 23>,
					/bits/ 8 <3 28 22 18 16 14 22 18 16 14 18 16 14 16 14 14>,
					/bits/ 8 <4 63 63 63 63 63 63 63 63 63 63 63 63 63 63 63>;
					paths-ru-bf =
					/bits/ 8 <6 43 31 24 19 15 37 30 25 21 33 28 25 31 27 29>,
					/bits/ 8 <1 41 29 22 17 13 35 28 23 19 31 26 23 29 25 27>,
					/bits/ 8 <2 37 25 18 13 9 31 24 19 15 27 22 19 25 21 23>,
					/bits/ 8 <3 28 16 9 4 0 22 15 10 6 18 13 10 16 12 14>,
					/bits/ 8 <4 63 63 63 63 63 63 63 63 63 63 63 63 63 63 63>;
				};
				r9 {
					channels = <108 108>;
					txs-delta = <0 0 0>;
					rates-cck = /bits/ 8 <63 63 63 63>;
					rates-ofdm = /bits/ 8 <44 44 44 44 44 44 44 44>;
					rates-mcs =
					/bits/ 8 <1 43 43 43 43 43 43 43 43 43 43>,
					/bits/ 8 <1 42 42 42 42 42 42 42 42 42 42>,
					/bits/ 8 <1 37 37 37 37 37 37 37 37 37 37>,
					/bits/ 8 <1 28 28 28 28 28 28 28 28 28 28>;
					rates-ru =
					/bits/ 8 <4 43 43 43 43 43 43 43 43 43 43 43 43>,
					/bits/ 8 <1 42 42 42 42 42 42 42 42 42 42 42 42>,
					/bits/ 8 <1 37 37 37 37 37 37 37 37 37 37 37 37>,
					/bits/ 8 <1 28 28 28 28 28 28 28 28 28 28 28 28>;
					rates-eht =
					/bits/ 8 <4 43 43 43 43 43 43 43 43 43 43 43 43 43 43 43 43>,
					/bits/ 8 <1 42 42 42 42 42 42 42 42 42 42 42 42 42 42 42 42>,
					/bits/ 8 <1 37 37 37 37 37 37 37 37 37 37 37 37 37 37 37 37>,
					/bits/ 8 <1 28 28 28 28 28 28 28 28 28 28 28 28 28 28 28 28>,
					/bits/ 8 <1 63 63 63 63 63 63 63 63 63 63 63 63 63 63 63 63>,
					/bits/ 8 <2 43 43 43 43 43 43 43 43 43 43 43 43 43 43 43 43>,
					/bits/ 8 <1 37 37 37 37 37 37 37 37 37 37 37 37 37 37 37 37>,
					/bits/ 8 <2 28 28 28 28 28 28 28 28 28 28 28 28 28 28 28 28>,
					/bits/ 8 <3 63 63 63 63 63 63 63 63 63 63 63 63 63 63 63 63>;
					paths-cck = /bits/ 8 <63 63 63 63 63>;
					paths-ofdm = /bits/ 8 <44 38 34 32 30>;
					paths-ofdm-bf = /bits/ 8 <32 25 20 16>;
					paths-ru =
					/bits/ 8 <6 43 37 33 31 29 37 33 31 29 33 31 29 31 29 29>,
					/bits/ 8 <1 42 36 32 30 28 36 32 30 28 32 30 28 30 28 28>,
					/bits/ 8 <2 37 31 27 25 23 31 27 25 23 27 25 23 25 23 23>,
					/bits/ 8 <3 28 22 18 16 14 22 18 16 14 18 16 14 16 14 14>,
					/bits/ 8 <4 63 63 63 63 63 63 63 63 63 63 63 63 63 63 63>;
					paths-ru-bf =
					/bits/ 8 <6 43 31 24 19 15 37 30 25 21 33 28 25 31 27 29>,
					/bits/ 8 <1 42 30 23 18 14 36 29 24 20 32 27 24 30 26 28>,
					/bits/ 8 <2 37 25 18 13 9 31 24 19 15 27 22 19 25 21 23>,
					/bits/ 8 <3 28 16 9 4 0 22 15 10 6 18 13 10 16 12 14>,
					/bits/ 8 <4 63 63 63 63 63 63 63 63 63 63 63 63 63 63 63>;
				};
				r10 {
					channels = <112 112>;
					txs-delta = <0 0 0>;
					rates-cck = /bits/ 8 <63 63 63 63>;
					rates-ofdm = /bits/ 8 <44 44 44 44 44 44 44 44>;
					rates-mcs =
					/bits/ 8 <1 43 43 43 43 43 43 43 43 43 43>,
					/bits/ 8 <1 42 42 42 42 42 42 42 42 42 42>,
					/bits/ 8 <1 37 37 37 37 37 37 37 37 37 37>,
					/bits/ 8 <1 35 35 35 35 35 35 35 35 35 35>;
					rates-ru =
					/bits/ 8 <4 43 43 43 43 43 43 43 43 43 43 43 43>,
					/bits/ 8 <1 42 42 42 42 42 42 42 42 42 42 42 42>,
					/bits/ 8 <1 37 37 37 37 37 37 37 37 37 37 37 37>,
					/bits/ 8 <1 35 35 35 35 35 35 35 35 35 35 35 35>;
					rates-eht =
					/bits/ 8 <4 43 43 43 43 43 43 43 43 43 43 43 43 43 43 43 43>,
					/bits/ 8 <1 42 42 42 42 42 42 42 42 42 42 42 42 42 42 42 42>,
					/bits/ 8 <1 37 37 37 37 37 37 37 37 37 37 37 37 37 37 37 37>,
					/bits/ 8 <1 35 35 35 35 35 35 35 35 35 35 35 35 35 35 35 35>,
					/bits/ 8 <1 63 63 63 63 63 63 63 63 63 63 63 63 63 63 63 63>,
					/bits/ 8 <2 43 43 43 43 43 43 43 43 43 43 43 43 43 43 43 43>,
					/bits/ 8 <1 37 37 37 37 37 37 37 37 37 37 37 37 37 37 37 37>,
					/bits/ 8 <2 35 35 35 35 35 35 35 35 35 35 35 35 35 35 35 35>,
					/bits/ 8 <3 63 63 63 63 63 63 63 63 63 63 63 63 63 63 63 63>;
					paths-cck = /bits/ 8 <63 63 63 63 63>;
					paths-ofdm = /bits/ 8 <44 38 34 32 30>;
					paths-ofdm-bf = /bits/ 8 <32 25 20 16>;
					paths-ru =
					/bits/ 8 <6 43 37 33 31 29 37 33 31 29 33 31 29 31 29 29>,
					/bits/ 8 <1 42 36 32 30 28 36 32 30 28 32 30 28 30 28 28>,
					/bits/ 8 <2 37 31 27 25 23 31 27 25 23 27 25 23 25 23 23>,
					/bits/ 8 <3 35 29 25 23 21 29 25 23 21 25 23 21 23 21 21>,
					/bits/ 8 <4 63 63 63 63 63 63 63 63 63 63 63 63 63 63 63>;
					paths-ru-bf =
					/bits/ 8 <6 43 31 24 19 15 37 30 25 21 33 28 25 31 27 29>,
					/bits/ 8 <1 42 30 23 18 14 36 29 24 20 32 27 24 30 26 28>,
					/bits/ 8 <2 37 25 18 13 9 31 24 19 15 27 22 19 25 21 23>,
					/bits/ 8 <3 35 23 16 11 7 29 22 17 13 25 20 17 23 19 21>,
					/bits/ 8 <4 63 63 63 63 63 63 63 63 63 63 63 63 63 63 63>;
				};
				r11 {
					channels = <116 116>;
					txs-delta = <0 0 0>;
					rates-cck = /bits/ 8 <63 63 63 63>;
					rates-ofdm = /bits/ 8 <45 45 45 45 45 45 45 45>;
					rates-mcs =
					/bits/ 8 <1 45 45 45 45 45 45 45 45 45 45>,
					/bits/ 8 <1 42 42 42 42 42 42 42 42 42 42>,
					/bits/ 8 <1 37 37 37 37 37 37 37 37 37 37>,
					/bits/ 8 <1 35 35 35 35 35 35 35 35 35 35>;
					rates-ru =
					/bits/ 8 <4 45 45 45 45 45 45 45 45 45 45 45 45>,
					/bits/ 8 <1 42 42 42 42 42 42 42 42 42 42 42 42>,
					/bits/ 8 <1 37 37 37 37 37 37 37 37 37 37 37 37>,
					/bits/ 8 <1 35 35 35 35 35 35 35 35 35 35 35 35>;
					rates-eht =
					/bits/ 8 <4 45 45 45 45 45 45 45 45 45 45 45 45 45 45 45 45>,
					/bits/ 8 <1 42 42 42 42 42 42 42 42 42 42 42 42 42 42 42 42>,
					/bits/ 8 <1 37 37 37 37 37 37 37 37 37 37 37 37 37 37 37 37>,
					/bits/ 8 <1 35 35 35 35 35 35 35 35 35 35 35 35 35 35 35 35>,
					/bits/ 8 <1 63 63 63 63 63 63 63 63 63 63 63 63 63 63 63 63>,
					/bits/ 8 <2 45 45 45 45 45 45 45 45 45 45 45 45 45 45 45 45>,
					/bits/ 8 <1 37 37 37 37 37 37 37 37 37 37 37 37 37 37 37 37>,
					/bits/ 8 <2 35 35 35 35 35 35 35 35 35 35 35 35 35 35 35 35>,
					/bits/ 8 <3 63 63 63 63 63 63 63 63 63 63 63 63 63 63 63 63>;
					paths-cck = /bits/ 8 <63 63 63 63 63>;
					paths-ofdm = /bits/ 8 <45 39 35 33 31>;
					paths-ofdm-bf = /bits/ 8 <33 26 21 17>;
					paths-ru =
					/bits/ 8 <6 45 39 35 33 31 39 35 33 31 35 33 31 33 31 31>,
					/bits/ 8 <1 42 36 32 30 28 36 32 30 28 32 30 28 30 28 28>,
					/bits/ 8 <2 37 31 27 25 23 31 27 25 23 27 25 23 25 23 23>,
					/bits/ 8 <3 35 29 25 23 21 29 25 23 21 25 23 21 23 21 21>,
					/bits/ 8 <4 63 63 63 63 63 63 63 63 63 63 63 63 63 63 63>;
					paths-ru-bf =
					/bits/ 8 <6 45 33 26 21 17 39 32 27 23 35 30 27 33 29 31>,
					/bits/ 8 <1 42 30 23 18 14 36 29 24 20 32 27 24 30 26 28>,
					/bits/ 8 <2 37 25 18 13 9 31 24 19 15 27 22 19 25 21 23>,
					/bits/ 8 <3 35 23 16 11 7 29 22 17 13 25 20 17 23 19 21>,
					/bits/ 8 <4 63 63 63 63 63 63 63 63 63 63 63 63 63 63 63>;
				};
				r12 {
					channels = <120 132>;
					txs-delta = <0 0 0>;
					rates-cck = /bits/ 8 <63 63 63 63>;
					rates-ofdm = /bits/ 8 <45 45 45 45 45 45 45 45>;
					rates-mcs =
					/bits/ 8 <1 45 45 45 45 45 45 45 45 45 45>,
					/bits/ 8 <1 42 42 42 42 42 42 42 42 42 42>,
					/bits/ 8 <1 41 41 41 41 41 41 41 41 41 41>,
					/bits/ 8 <1 35 35 35 35 35 35 35 35 35 35>;
					rates-ru =
					/bits/ 8 <4 45 45 45 45 45 45 45 45 45 45 45 45>,
					/bits/ 8 <1 42 42 42 42 42 42 42 42 42 42 42 42>,
					/bits/ 8 <1 41 41 41 41 41 41 41 41 41 41 41 41>,
					/bits/ 8 <1 35 35 35 35 35 35 35 35 35 35 35 35>;
					rates-eht =
					/bits/ 8 <4 45 45 45 45 45 45 45 45 45 45 45 45 45 45 45 45>,
					/bits/ 8 <1 42 42 42 42 42 42 42 42 42 42 42 42 42 42 42 42>,
					/bits/ 8 <1 41 41 41 41 41 41 41 41 41 41 41 41 41 41 41 41>,
					/bits/ 8 <1 35 35 35 35 35 35 35 35 35 35 35 35 35 35 35 35>,
					/bits/ 8 <1 63 63 63 63 63 63 63 63 63 63 63 63 63 63 63 63>,
					/bits/ 8 <2 45 45 45 45 45 45 45 45 45 45 45 45 45 45 45 45>,
					/bits/ 8 <1 41 41 41 41 41 41 41 41 41 41 41 41 41 41 41 41>,
					/bits/ 8 <2 35 35 35 35 35 35 35 35 35 35 35 35 35 35 35 35>,
					/bits/ 8 <3 63 63 63 63 63 63 63 63 63 63 63 63 63 63 63 63>;
					paths-cck = /bits/ 8 <63 63 63 63 63>;
					paths-ofdm = /bits/ 8 <45 39 35 33 31>;
					paths-ofdm-bf = /bits/ 8 <33 26 21 17>;
					paths-ru =
					/bits/ 8 <6 45 39 35 33 31 39 35 33 31 35 33 31 33 31 31>,
					/bits/ 8 <1 42 36 32 30 28 36 32 30 28 32 30 28 30 28 28>,
					/bits/ 8 <2 41 35 31 29 27 35 31 29 27 31 29 27 29 27 27>,
					/bits/ 8 <3 35 29 25 23 21 29 25 23 21 25 23 21 23 21 21>,
					/bits/ 8 <4 63 63 63 63 63 63 63 63 63 63 63 63 63 63 63>;
					paths-ru-bf =
					/bits/ 8 <6 45 33 26 21 17 39 32 27 23 35 30 27 33 29 31>,
					/bits/ 8 <1 42 30 23 18 14 36 29 24 20 32 27 24 30 26 28>,
					/bits/ 8 <2 41 29 22 17 13 35 28 23 19 31 26 23 29 25 27>,
					/bits/ 8 <3 35 23 16 11 7 29 22 17 13 25 20 17 23 19 21>,
					/bits/ 8 <4 63 63 63 63 63 63 63 63 63 63 63 63 63 63 63>;
				};
				r13 {
					channels = <136 136>;
					txs-delta = <0 0 0>;
					rates-cck = /bits/ 8 <63 63 63 63>;
					rates-ofdm = /bits/ 8 <45 45 45 45 45 45 45 45>;
					rates-mcs =
					/bits/ 8 <1 45 45 45 45 45 45 45 45 45 45>,
					/bits/ 8 <1 42 42 42 42 42 42 42 42 42 42>,
					/bits/ 8 <1 46 46 46 46 46 46 46 46 46 46>,
					/bits/ 8 <1 35 35 35 35 35 35 35 35 35 35>;
					rates-ru =
					/bits/ 8 <4 45 45 45 45 45 45 45 45 45 45 45 45>,
					/bits/ 8 <1 42 42 42 42 42 42 42 42 42 42 42 42>,
					/bits/ 8 <1 46 46 46 46 46 46 46 46 46 46 46 46>,
					/bits/ 8 <1 35 35 35 35 35 35 35 35 35 35 35 35>;
					rates-eht =
					/bits/ 8 <4 45 45 45 45 45 45 45 45 45 45 45 45 45 45 45 45>,
					/bits/ 8 <1 42 42 42 42 42 42 42 42 42 42 42 42 42 42 42 42>,
					/bits/ 8 <1 46 46 46 46 46 46 46 46 46 46 46 46 46 46 46 46>,
					/bits/ 8 <1 35 35 35 35 35 35 35 35 35 35 35 35 35 35 35 35>,
					/bits/ 8 <1 63 63 63 63 63 63 63 63 63 63 63 63 63 63 63 63>,
					/bits/ 8 <2 45 45 45 45 45 45 45 45 45 45 45 45 45 45 45 45>,
					/bits/ 8 <1 46 46 46 46 46 46 46 46 46 46 46 46 46 46 46 46>,
					/bits/ 8 <2 35 35 35 35 35 35 35 35 35 35 35 35 35 35 35 35>,
					/bits/ 8 <3 63 63 63 63 63 63 63 63 63 63 63 63 63 63 63 63>;
					paths-cck = /bits/ 8 <63 63 63 63 63>;
					paths-ofdm = /bits/ 8 <45 39 35 33 31>;
					paths-ofdm-bf = /bits/ 8 <33 26 21 17>;
					paths-ru =
					/bits/ 8 <6 45 39 35 33 31 39 35 33 31 35 33 31 33 31 31>,
					/bits/ 8 <1 42 36 32 30 28 36 32 30 28 32 30 28 30 28 28>,
					/bits/ 8 <2 46 40 36 34 32 40 36 34 32 36 34 32 34 32 32>,
					/bits/ 8 <3 35 29 25 23 21 29 25 23 21 25 23 21 23 21 21>,
					/bits/ 8 <4 63 63 63 63 63 63 63 63 63 63 63 63 63 63 63>;
					paths-ru-bf =
					/bits/ 8 <6 45 33 26 21 17 39 32 27 23 35 30 27 33 29 31>,
					/bits/ 8 <1 42 30 23 18 14 36 29 24 20 32 27 24 30 26 28>,
					/bits/ 8 <2 46 34 27 22 18 40 33 28 24 36 31 28 34 30 32>,
					/bits/ 8 <3 35 23 16 11 7 29 22 17 13 25 20 17 23 19 21>,
					/bits/ 8 <4 63 63 63 63 63 63 63 63 63 63 63 63 63 63 63>;
				};
				r14 {
					channels = <140 140>;
					txs-delta = <0 0 0>;
					rates-cck = /bits/ 8 <63 63 63 63>;
					rates-ofdm = /bits/ 8 <41 41 41 41 41 41 41 41>;
					rates-mcs =
					/bits/ 8 <1 40 40 40 40 40 40 40 40 40 40>,
					/bits/ 8 <2 46 46 46 46 46 46 46 46 46 46>,
					/bits/ 8 <1 35 35 35 35 35 35 35 35 35 35>;
					rates-ru =
					/bits/ 8 <4 40 40 40 40 40 40 40 40 40 40 40 40>,
					/bits/ 8 <2 46 46 46 46 46 46 46 46 46 46 46 46>,
					/bits/ 8 <1 35 35 35 35 35 35 35 35 35 35 35 35>;
					rates-eht =
					/bits/ 8 <4 40 40 40 40 40 40 40 40 40 40 40 40 40 40 40 40>,
					/bits/ 8 <2 46 46 46 46 46 46 46 46 46 46 46 46 46 46 46 46>,
					/bits/ 8 <1 35 35 35 35 35 35 35 35 35 35 35 35 35 35 35 35>,
					/bits/ 8 <1 63 63 63 63 63 63 63 63 63 63 63 63 63 63 63 63>,
					/bits/ 8 <2 40 40 40 40 40 40 40 40 40 40 40 40 40 40 40 40>,
					/bits/ 8 <1 46 46 46 46 46 46 46 46 46 46 46 46 46 46 46 46>,
					/bits/ 8 <2 35 35 35 35 35 35 35 35 35 35 35 35 35 35 35 35>,
					/bits/ 8 <3 63 63 63 63 63 63 63 63 63 63 63 63 63 63 63 63>;
					paths-cck = /bits/ 8 <63 63 63 63 63>;
					paths-ofdm = /bits/ 8 <41 35 31 29 27>;
					paths-ofdm-bf = /bits/ 8 <29 22 17 13>;
					paths-ru =
					/bits/ 8 <6 40 34 30 28 26 34 30 28 26 30 28 26 28 26 26>,
					/bits/ 8 <3 46 40 36 34 32 40 36 34 32 36 34 32 34 32 32>,
					/bits/ 8 <3 35 29 25 23 21 29 25 23 21 25 23 21 23 21 21>,
					/bits/ 8 <4 63 63 63 63 63 63 63 63 63 63 63 63 63 63 63>;
					paths-ru-bf =
					/bits/ 8 <6 40 28 21 16 12 34 27 22 18 30 25 22 28 24 26>,
					/bits/ 8 <3 46 34 27 22 18 40 33 28 24 36 31 28 34 30 32>,
					/bits/ 8 <3 35 23 16 11 7 29 22 17 13 25 20 17 23 19 21>,
					/bits/ 8 <4 63 63 63 63 63 63 63 63 63 63 63 63 63 63 63>;
				};
				r15 {
					channels = <144 144>;
					txs-delta = <0 0 0>;
					rates-cck = /bits/ 8 <63 63 63 63>;
					rates-ofdm = /bits/ 8 <43 43 43 43 43 43 43 43>;
					rates-mcs =
					/bits/ 8 <1 43 43 43 43 43 43 43 43 43 43>,
					/bits/ 8 <2 46 46 46 46 46 46 46 46 46 46>,
					/bits/ 8 <1 35 35 35 35 35 35 35 35 35 35>;
					rates-ru =
					/bits/ 8 <4 43 43 43 43 43 43 43 43 43 43 43 43>,
					/bits/ 8 <2 46 46 46 46 46 46 46 46 46 46 46 46>,
					/bits/ 8 <1 35 35 35 35 35 35 35 35 35 35 35 35>;
					rates-eht =
					/bits/ 8 <4 43 43 43 43 43 43 43 43 43 43 43 43 43 43 43 43>,
					/bits/ 8 <2 46 46 46 46 46 46 46 46 46 46 46 46 46 46 46 46>,
					/bits/ 8 <1 35 35 35 35 35 35 35 35 35 35 35 35 35 35 35 35>,
					/bits/ 8 <1 63 63 63 63 63 63 63 63 63 63 63 63 63 63 63 63>,
					/bits/ 8 <2 43 43 43 43 43 43 43 43 43 43 43 43 43 43 43 43>,
					/bits/ 8 <1 46 46 46 46 46 46 46 46 46 46 46 46 46 46 46 46>,
					/bits/ 8 <2 35 35 35 35 35 35 35 35 35 35 35 35 35 35 35 35>,
					/bits/ 8 <3 63 63 63 63 63 63 63 63 63 63 63 63 63 63 63 63>;
					paths-cck = /bits/ 8 <63 63 63 63 63>;
					paths-ofdm = /bits/ 8 <43 37 33 31 29>;
					paths-ofdm-bf = /bits/ 8 <31 24 19 15>;
					paths-ru =
					/bits/ 8 <6 43 37 33 31 29 37 33 31 29 33 31 29 31 29 29>,
					/bits/ 8 <3 46 40 36 34 32 40 36 34 32 36 34 32 34 32 32>,
					/bits/ 8 <3 35 29 25 23 21 29 25 23 21 25 23 21 23 21 21>,
					/bits/ 8 <4 63 63 63 63 63 63 63 63 63 63 63 63 63 63 63>;
					paths-ru-bf =
					/bits/ 8 <6 43 31 24 19 15 37 30 25 21 33 28 25 31 27 29>,
					/bits/ 8 <3 46 34 27 22 18 40 33 28 24 36 31 28 34 30 32>,
					/bits/ 8 <3 35 23 16 11 7 29 22 17 13 25 20 17 23 19 21>,
					/bits/ 8 <4 63 63 63 63 63 63 63 63 63 63 63 63 63 63 63>;
				};
				r16 {
					channels = <149 149>;
					txs-delta = <0 0 0>;
					rates-cck = /bits/ 8 <63 63 63 63>;
					rates-ofdm = /bits/ 8 <57 57 57 57 57 57 57 57>;
					rates-mcs =
					/bits/ 8 <1 55 55 55 55 55 55 55 55 55 55>,
					/bits/ 8 <1 52 52 52 52 52 52 52 52 52 52>,
					/bits/ 8 <1 46 46 46 46 46 46 46 46 46 46>,
					/bits/ 8 <1 35 35 35 35 35 35 35 35 35 35>;
					rates-ru =
					/bits/ 8 <4 55 55 55 55 55 55 55 55 55 55 55 55>,
					/bits/ 8 <1 52 52 52 52 52 52 52 52 52 52 52 52>,
					/bits/ 8 <1 46 46 46 46 46 46 46 46 46 46 46 46>,
					/bits/ 8 <1 35 35 35 35 35 35 35 35 35 35 35 35>;
					rates-eht =
					/bits/ 8 <4 55 55 55 55 55 55 55 55 55 55 55 55 55 55 55 55>,
					/bits/ 8 <1 52 52 52 52 52 52 52 52 52 52 52 52 52 52 52 52>,
					/bits/ 8 <1 46 46 46 46 46 46 46 46 46 46 46 46 46 46 46 46>,
					/bits/ 8 <1 35 35 35 35 35 35 35 35 35 35 35 35 35 35 35 35>,
					/bits/ 8 <1 63 63 63 63 63 63 63 63 63 63 63 63 63 63 63 63>,
					/bits/ 8 <2 55 55 55 55 55 55 55 55 55 55 55 55 55 55 55 55>,
					/bits/ 8 <1 46 46 46 46 46 46 46 46 46 46 46 46 46 46 46 46>,
					/bits/ 8 <2 35 35 35 35 35 35 35 35 35 35 35 35 35 35 35 35>,
					/bits/ 8 <3 63 63 63 63 63 63 63 63 63 63 63 63 63 63 63 63>;
					paths-cck = /bits/ 8 <63 63 63 63 63>;
					paths-ofdm = /bits/ 8 <57 51 47 45 43>;
					paths-ofdm-bf = /bits/ 8 <45 38 33 29>;
					paths-ru =
					/bits/ 8 <6 55 49 45 43 41 49 45 43 41 45 43 41 43 41 41>,
					/bits/ 8 <1 52 46 42 40 38 46 42 40 38 42 40 38 40 38 38>,
					/bits/ 8 <2 46 40 36 34 32 40 36 34 32 36 34 32 34 32 32>,
					/bits/ 8 <3 35 29 25 23 21 29 25 23 21 25 23 21 23 21 21>,
					/bits/ 8 <4 63 63 63 63 63 63 63 63 63 63 63 63 63 63 63>;
					paths-ru-bf =
					/bits/ 8 <6 55 43 36 31 27 49 42 37 33 45 40 37 43 39 41>,
					/bits/ 8 <1 52 40 33 28 24 46 39 34 30 42 37 34 40 36 38>,
					/bits/ 8 <2 46 34 27 22 18 40 33 28 24 36 31 28 34 30 32>,
					/bits/ 8 <3 35 23 16 11 7 29 22 17 13 25 20 17 23 19 21>,
					/bits/ 8 <4 63 63 63 63 63 63 63 63 63 63 63 63 63 63 63>;
				};
				r17 {
					channels = <153 153>;
					txs-delta = <0 0 0>;
					rates-cck = /bits/ 8 <63 63 63 63>;
					rates-ofdm = /bits/ 8 <57 57 57 57 57 57 57 57>;
					rates-mcs =
					/bits/ 8 <1 55 55 55 55 55 55 55 55 55 55>,
					/bits/ 8 <1 52 52 52 52 52 52 52 52 52 52>,
					/bits/ 8 <1 48 48 48 48 48 48 48 48 48 48>,
					/bits/ 8 <1 35 35 35 35 35 35 35 35 35 35>;
					rates-ru =
					/bits/ 8 <4 55 55 55 55 55 55 55 55 55 55 55 55>,
					/bits/ 8 <1 52 52 52 52 52 52 52 52 52 52 52 52>,
					/bits/ 8 <1 48 48 48 48 48 48 48 48 48 48 48 48>,
					/bits/ 8 <1 35 35 35 35 35 35 35 35 35 35 35 35>;
					rates-eht =
					/bits/ 8 <4 55 55 55 55 55 55 55 55 55 55 55 55 55 55 55 55>,
					/bits/ 8 <1 52 52 52 52 52 52 52 52 52 52 52 52 52 52 52 52>,
					/bits/ 8 <1 48 48 48 48 48 48 48 48 48 48 48 48 48 48 48 48>,
					/bits/ 8 <1 35 35 35 35 35 35 35 35 35 35 35 35 35 35 35 35>,
					/bits/ 8 <1 63 63 63 63 63 63 63 63 63 63 63 63 63 63 63 63>,
					/bits/ 8 <2 55 55 55 55 55 55 55 55 55 55 55 55 55 55 55 55>,
					/bits/ 8 <1 48 48 48 48 48 48 48 48 48 48 48 48 48 48 48 48>,
					/bits/ 8 <2 35 35 35 35 35 35 35 35 35 35 35 35 35 35 35 35>,
					/bits/ 8 <3 63 63 63 63 63 63 63 63 63 63 63 63 63 63 63 63>;
					paths-cck = /bits/ 8 <63 63 63 63 63>;
					paths-ofdm = /bits/ 8 <57 51 47 45 43>;
					paths-ofdm-bf = /bits/ 8 <45 38 33 29>;
					paths-ru =
					/bits/ 8 <6 55 49 45 43 41 49 45 43 41 45 43 41 43 41 41>,
					/bits/ 8 <1 52 46 42 40 38 46 42 40 38 42 40 38 40 38 38>,
					/bits/ 8 <2 48 42 38 36 34 42 38 36 34 38 36 34 36 34 34>,
					/bits/ 8 <3 35 29 25 23 21 29 25 23 21 25 23 21 23 21 21>,
					/bits/ 8 <4 63 63 63 63 63 63 63 63 63 63 63 63 63 63 63>;
					paths-ru-bf =
					/bits/ 8 <6 55 43 36 31 27 49 42 37 33 45 40 37 43 39 41>,
					/bits/ 8 <1 52 40 33 28 24 46 39 34 30 42 37 34 40 36 38>,
					/bits/ 8 <2 48 36 29 24 20 42 35 30 26 38 33 30 36 32 34>,
					/bits/ 8 <3 35 23 16 11 7 29 22 17 13 25 20 17 23 19 21>,
					/bits/ 8 <4 63 63 63 63 63 63 63 63 63 63 63 63 63 63 63>;
				};
				r18 {
					channels = <157 181>;
					txs-delta = <0 0 0>;
					rates-cck = /bits/ 8 <63 63 63 63>;
					rates-ofdm = /bits/ 8 <57 57 57 57 57 57 57 57>;
					rates-mcs =
					/bits/ 8 <2 54 54 54 54 54 54 54 54 54 54>,
					/bits/ 8 <1 48 48 48 48 48 48 48 48 48 48>,
					/bits/ 8 <1 35 35 35 35 35 35 35 35 35 35>;
					rates-ru =
					/bits/ 8 <5 54 54 54 54 54 54 54 54 54 54 54 54>,
					/bits/ 8 <1 48 48 48 48 48 48 48 48 48 48 48 48>,
					/bits/ 8 <1 35 35 35 35 35 35 35 35 35 35 35 35>;
					rates-eht =
					/bits/ 8 <5 54 54 54 54 54 54 54 54 54 54 54 54 54 54 54 54>,
					/bits/ 8 <1 48 48 48 48 48 48 48 48 48 48 48 48 48 48 48 48>,
					/bits/ 8 <1 35 35 35 35 35 35 35 35 35 35 35 35 35 35 35 35>,
					/bits/ 8 <1 63 63 63 63 63 63 63 63 63 63 63 63 63 63 63 63>,
					/bits/ 8 <2 54 54 54 54 54 54 54 54 54 54 54 54 54 54 54 54>,
					/bits/ 8 <1 48 48 48 48 48 48 48 48 48 48 48 48 48 48 48 48>,
					/bits/ 8 <2 35 35 35 35 35 35 35 35 35 35 35 35 35 35 35 35>,
					/bits/ 8 <3 63 63 63 63 63 63 63 63 63 63 63 63 63 63 63 63>;
					paths-cck = /bits/ 8 <63 63 63 63 63>;
					paths-ofdm = /bits/ 8 <57 51 47 45 43>;
					paths-ofdm-bf = /bits/ 8 <45 38 33 29>;
					paths-ru =
					/bits/ 8 <7 54 48 44 42 40 48 44 42 40 44 42 40 42 40 40>,
					/bits/ 8 <2 48 42 38 36 34 42 38 36 34 38 36 34 36 34 34>,
					/bits/ 8 <3 35 29 25 23 21 29 25 23 21 25 23 21 23 21 21>,
					/bits/ 8 <4 63 63 63 63 63 63 63 63 63 63 63 63 63 63 63>;
					paths-ru-bf =
					/bits/ 8 <7 54 42 35 30 26 48 41 36 32 44 39 36 42 38 40>,
					/bits/ 8 <2 48 36 29 24 20 42 35 30 26 38 33 30 36 32 34>,
					/bits/ 8 <3 35 23 16 11 7 29 22 17 13 25 20 17 23 19 21>,
					/bits/ 8 <4 63 63 63 63 63 63 63 63 63 63 63 63 63 63 63>;
				};
			};
			txpower-6g {
				r0 {
					channels = <1 41>;
					txs-delta = <0 0 0>;
					rates-cck = /bits/ 8 <63 63 63 63>;
					rates-ofdm = /bits/ 8 <22 22 22 22 22 22 22 22>;
					rates-mcs =
					/bits/ 8 <4 63 63 63 63 63 63 63 63 63 63>;
					rates-ru =
					/bits/ 8 <4 22 22 22 22 22 22 22 22 22 22 22 22>,
					/bits/ 8 <1 27 27 27 27 27 27 27 27 27 27 27 27>,
					/bits/ 8 <1 33 33 33 33 33 33 33 33 33 33 33 33>,
					/bits/ 8 <1 38 38 38 38 38 38 38 38 38 38 38 38>;
					rates-eht =
					/bits/ 8 <4 22 22 22 22 22 22 22 22 22 22 22 22 22 22 22 22>,
					/bits/ 8 <1 27 27 27 27 27 27 27 27 27 27 27 27 27 27 27 27>,
					/bits/ 8 <1 33 33 33 33 33 33 33 33 33 33 33 33 33 33 33 33>,
					/bits/ 8 <1 38 38 38 38 38 38 38 38 38 38 38 38 38 38 38 38>,
					/bits/ 8 <1 40 40 40 40 40 40 40 40 40 40 40 40 40 40 40 40>,
					/bits/ 8 <2 22 22 22 22 22 22 22 22 22 22 22 22 22 22 22 22>,
					/bits/ 8 <1 33 33 33 33 33 33 33 33 33 33 33 33 33 33 33 33>,
					/bits/ 8 <2 38 38 38 38 38 38 38 38 38 38 38 38 38 38 38 38>,
					/bits/ 8 <3 40 40 40 40 40 40 40 40 40 40 40 40 40 40 40 40>;
					paths-cck = /bits/ 8 <63 63 63 63 63>;
					paths-ofdm = /bits/ 8 <22 16 12 10 8>;
					paths-ofdm-bf = /bits/ 8 <10 3 0 0>;
					paths-ru =
					/bits/ 8 <6 22 16 12 10 8 16 12 10 8 12 10 8 10 8 8>,
					/bits/ 8 <1 27 21 17 15 13 21 17 15 13 17 15 13 15 13 13>,
					/bits/ 8 <2 33 27 23 21 19 27 23 21 19 23 21 19 21 19 19>,
					/bits/ 8 <3 38 32 28 26 24 32 28 26 24 28 26 24 26 24 24>,
					/bits/ 8 <4 40 34 30 28 26 34 30 28 26 30 28 26 28 26 26>;
					paths-ru-bf =
					/bits/ 8 <6 22 10 3 0 0 16 9 4 0 12 7 4 10 6 8>,
					/bits/ 8 <1 27 15 8 3 0 21 14 9 5 17 12 9 15 11 13>,
					/bits/ 8 <2 33 21 14 9 5 27 20 15 11 23 18 15 21 17 19>,
					/bits/ 8 <3 38 26 19 14 10 32 25 20 16 28 23 20 26 22 24>,
					/bits/ 8 <4 40 28 21 16 12 34 27 22 18 30 25 22 28 24 26>;
				};
				r1 {
					channels = <45 49>;
					txs-delta = <0 0 0>;
					rates-cck = /bits/ 8 <63 63 63 63>;
					rates-ofdm = /bits/ 8 <22 22 22 22 22 22 22 22>;
					rates-mcs =
					/bits/ 8 <4 63 63 63 63 63 63 63 63 63 63>;
					rates-ru =
					/bits/ 8 <4 22 22 22 22 22 22 22 22 22 22 22 22>,
					/bits/ 8 <1 27 27 27 27 27 27 27 27 27 27 27 27>,
					/bits/ 8 <1 33 33 33 33 33 33 33 33 33 33 33 33>,
					/bits/ 8 <1 37 37 37 37 37 37 37 37 37 37 37 37>;
					rates-eht =
					/bits/ 8 <4 22 22 22 22 22 22 22 22 22 22 22 22 22 22 22 22>,
					/bits/ 8 <1 27 27 27 27 27 27 27 27 27 27 27 27 27 27 27 27>,
					/bits/ 8 <1 33 33 33 33 33 33 33 33 33 33 33 33 33 33 33 33>,
					/bits/ 8 <1 37 37 37 37 37 37 37 37 37 37 37 37 37 37 37 37>,
					/bits/ 8 <1 40 40 40 40 40 40 40 40 40 40 40 40 40 40 40 40>,
					/bits/ 8 <2 22 22 22 22 22 22 22 22 22 22 22 22 22 22 22 22>,
					/bits/ 8 <1 33 33 33 33 33 33 33 33 33 33 33 33 33 33 33 33>,
					/bits/ 8 <2 37 37 37 37 37 37 37 37 37 37 37 37 37 37 37 37>,
					/bits/ 8 <3 40 40 40 40 40 40 40 40 40 40 40 40 40 40 40 40>;
					paths-cck = /bits/ 8 <63 63 63 63 63>;
					paths-ofdm = /bits/ 8 <22 16 12 10 8>;
					paths-ofdm-bf = /bits/ 8 <10 3 0 0>;
					paths-ru =
					/bits/ 8 <6 22 16 12 10 8 16 12 10 8 12 10 8 10 8 8>,
					/bits/ 8 <1 27 21 17 15 13 21 17 15 13 17 15 13 15 13 13>,
					/bits/ 8 <2 33 27 23 21 19 27 23 21 19 23 21 19 21 19 19>,
					/bits/ 8 <3 37 31 27 25 23 31 27 25 23 27 25 23 25 23 23>,
					/bits/ 8 <4 40 34 30 28 26 34 30 28 26 30 28 26 28 26 26>;
					paths-ru-bf =
					/bits/ 8 <6 22 10 3 0 0 16 9 4 0 12 7 4 10 6 8>,
					/bits/ 8 <1 27 15 8 3 0 21 14 9 5 17 12 9 15 11 13>,
					/bits/ 8 <2 33 21 14 9 5 27 20 15 11 23 18 15 21 17 19>,
					/bits/ 8 <3 37 25 18 13 9 31 24 19 15 27 22 19 25 21 23>,
					/bits/ 8 <4 40 28 21 16 12 34 27 22 18 30 25 22 28 24 26>;
				};
				r2 {
					channels = <53 57>;
					txs-delta = <0 0 0>;
					rates-cck = /bits/ 8 <63 63 63 63>;
					rates-ofdm = /bits/ 8 <22 22 22 22 22 22 22 22>;
					rates-mcs =
					/bits/ 8 <4 63 63 63 63 63 63 63 63 63 63>;
					rates-ru =
					/bits/ 8 <4 22 22 22 22 22 22 22 22 22 22 22 22>,
					/bits/ 8 <1 27 27 27 27 27 27 27 27 27 27 27 27>,
					/bits/ 8 <1 32 32 32 32 32 32 32 32 32 32 32 32>,
					/bits/ 8 <1 37 37 37 37 37 37 37 37 37 37 37 37>;
					rates-eht =
					/bits/ 8 <4 22 22 22 22 22 22 22 22 22 22 22 22 22 22 22 22>,
					/bits/ 8 <1 27 27 27 27 27 27 27 27 27 27 27 27 27 27 27 27>,
					/bits/ 8 <1 32 32 32 32 32 32 32 32 32 32 32 32 32 32 32 32>,
					/bits/ 8 <1 37 37 37 37 37 37 37 37 37 37 37 37 37 37 37 37>,
					/bits/ 8 <1 40 40 40 40 40 40 40 40 40 40 40 40 40 40 40 40>,
					/bits/ 8 <2 22 22 22 22 22 22 22 22 22 22 22 22 22 22 22 22>,
					/bits/ 8 <1 32 32 32 32 32 32 32 32 32 32 32 32 32 32 32 32>,
					/bits/ 8 <2 37 37 37 37 37 37 37 37 37 37 37 37 37 37 37 37>,
					/bits/ 8 <3 40 40 40 40 40 40 40 40 40 40 40 40 40 40 40 40>;
					paths-cck = /bits/ 8 <63 63 63 63 63>;
					paths-ofdm = /bits/ 8 <22 16 12 10 8>;
					paths-ofdm-bf = /bits/ 8 <10 3 0 0>;
					paths-ru =
					/bits/ 8 <6 22 16 12 10 8 16 12 10 8 12 10 8 10 8 8>,
					/bits/ 8 <1 27 21 17 15 13 21 17 15 13 17 15 13 15 13 13>,
					/bits/ 8 <2 32 26 22 20 18 26 22 20 18 22 20 18 20 18 18>,
					/bits/ 8 <3 37 31 27 25 23 31 27 25 23 27 25 23 25 23 23>,
					/bits/ 8 <4 40 34 30 28 26 34 30 28 26 30 28 26 28 26 26>;
					paths-ru-bf =
					/bits/ 8 <6 22 10 3 0 0 16 9 4 0 12 7 4 10 6 8>,
					/bits/ 8 <1 27 15 8 3 0 21 14 9 5 17 12 9 15 11 13>,
					/bits/ 8 <2 32 20 13 8 4 26 19 14 10 22 17 14 20 16 18>,
					/bits/ 8 <3 37 25 18 13 9 31 24 19 15 27 22 19 25 21 23>,
					/bits/ 8 <4 40 28 21 16 12 34 27 22 18 30 25 22 28 24 26>;
				};
				r3 {
					channels = <61 73>;
					txs-delta = <0 0 0>;
					rates-cck = /bits/ 8 <63 63 63 63>;
					rates-ofdm = /bits/ 8 <22 22 22 22 22 22 22 22>;
					rates-mcs =
					/bits/ 8 <4 63 63 63 63 63 63 63 63 63 63>;
					rates-ru =
					/bits/ 8 <4 22 22 22 22 22 22 22 22 22 22 22 22>,
					/bits/ 8 <1 27 27 27 27 27 27 27 27 27 27 27 27>,
					/bits/ 8 <1 32 32 32 32 32 32 32 32 32 32 32 32>,
					/bits/ 8 <1 37 37 37 37 37 37 37 37 37 37 37 37>;
					rates-eht =
					/bits/ 8 <4 22 22 22 22 22 22 22 22 22 22 22 22 22 22 22 22>,
					/bits/ 8 <1 27 27 27 27 27 27 27 27 27 27 27 27 27 27 27 27>,
					/bits/ 8 <1 32 32 32 32 32 32 32 32 32 32 32 32 32 32 32 32>,
					/bits/ 8 <1 37 37 37 37 37 37 37 37 37 37 37 37 37 37 37 37>,
					/bits/ 8 <1 42 42 42 42 42 42 42 42 42 42 42 42 42 42 42 42>,
					/bits/ 8 <2 22 22 22 22 22 22 22 22 22 22 22 22 22 22 22 22>,
					/bits/ 8 <1 32 32 32 32 32 32 32 32 32 32 32 32 32 32 32 32>,
					/bits/ 8 <2 37 37 37 37 37 37 37 37 37 37 37 37 37 37 37 37>,
					/bits/ 8 <3 42 42 42 42 42 42 42 42 42 42 42 42 42 42 42 42>;
					paths-cck = /bits/ 8 <63 63 63 63 63>;
					paths-ofdm = /bits/ 8 <22 16 12 10 8>;
					paths-ofdm-bf = /bits/ 8 <10 3 0 0>;
					paths-ru =
					/bits/ 8 <6 22 16 12 10 8 16 12 10 8 12 10 8 10 8 8>,
					/bits/ 8 <1 27 21 17 15 13 21 17 15 13 17 15 13 15 13 13>,
					/bits/ 8 <2 32 26 22 20 18 26 22 20 18 22 20 18 20 18 18>,
					/bits/ 8 <3 37 31 27 25 23 31 27 25 23 27 25 23 25 23 23>,
					/bits/ 8 <4 42 36 32 30 28 36 32 30 28 32 30 28 30 28 28>;
					paths-ru-bf =
					/bits/ 8 <6 22 10 3 0 0 16 9 4 0 12 7 4 10 6 8>,
					/bits/ 8 <1 27 15 8 3 0 21 14 9 5 17 12 9 15 11 13>,
					/bits/ 8 <2 32 20 13 8 4 26 19 14 10 22 17 14 20 16 18>,
					/bits/ 8 <3 37 25 18 13 9 31 24 19 15 27 22 19 25 21 23>,
					/bits/ 8 <4 42 30 23 18 14 36 29 24 20 32 27 24 30 26 28>;
				};
				r4 {
					channels = <77 93>;
					txs-delta = <0 0 0>;
					rates-cck = /bits/ 8 <63 63 63 63>;
					rates-ofdm = /bits/ 8 <22 22 22 22 22 22 22 22>;
					rates-mcs =
					/bits/ 8 <4 63 63 63 63 63 63 63 63 63 63>;
					rates-ru =
					/bits/ 8 <4 22 22 22 22 22 22 22 22 22 22 22 22>,
					/bits/ 8 <1 27 27 27 27 27 27 27 27 27 27 27 27>,
					/bits/ 8 <1 32 32 32 32 32 32 32 32 32 32 32 32>,
					/bits/ 8 <1 38 38 38 38 38 38 38 38 38 38 38 38>;
					rates-eht =
					/bits/ 8 <4 22 22 22 22 22 22 22 22 22 22 22 22 22 22 22 22>,
					/bits/ 8 <1 27 27 27 27 27 27 27 27 27 27 27 27 27 27 27 27>,
					/bits/ 8 <1 32 32 32 32 32 32 32 32 32 32 32 32 32 32 32 32>,
					/bits/ 8 <1 38 38 38 38 38 38 38 38 38 38 38 38 38 38 38 38>,
					/bits/ 8 <1 42 42 42 42 42 42 42 42 42 42 42 42 42 42 42 42>,
					/bits/ 8 <2 22 22 22 22 22 22 22 22 22 22 22 22 22 22 22 22>,
					/bits/ 8 <1 32 32 32 32 32 32 32 32 32 32 32 32 32 32 32 32>,
					/bits/ 8 <2 38 38 38 38 38 38 38 38 38 38 38 38 38 38 38 38>,
					/bits/ 8 <3 42 42 42 42 42 42 42 42 42 42 42 42 42 42 42 42>;
					paths-cck = /bits/ 8 <63 63 63 63 63>;
					paths-ofdm = /bits/ 8 <22 16 12 10 8>;
					paths-ofdm-bf = /bits/ 8 <10 3 0 0>;
					paths-ru =
					/bits/ 8 <6 22 16 12 10 8 16 12 10 8 12 10 8 10 8 8>,
					/bits/ 8 <1 27 21 17 15 13 21 17 15 13 17 15 13 15 13 13>,
					/bits/ 8 <2 32 26 22 20 18 26 22 20 18 22 20 18 20 18 18>,
					/bits/ 8 <3 38 32 28 26 24 32 28 26 24 28 26 24 26 24 24>,
					/bits/ 8 <4 42 36 32 30 28 36 32 30 28 32 30 28 30 28 28>;
					paths-ru-bf =
					/bits/ 8 <6 22 10 3 0 0 16 9 4 0 12 7 4 10 6 8>,
					/bits/ 8 <1 27 15 8 3 0 21 14 9 5 17 12 9 15 11 13>,
					/bits/ 8 <2 32 20 13 8 4 26 19 14 10 22 17 14 20 16 18>,
					/bits/ 8 <3 38 26 19 14 10 32 25 20 16 28 23 20 26 22 24>,
					/bits/ 8 <4 42 30 23 18 14 36 29 24 20 32 27 24 30 26 28>;
				};
				r5 {
					channels = <97 97>;
					txs-delta = <0 0 0>;
					rates-cck = /bits/ 8 <63 63 63 63>;
					rates-ofdm = /bits/ 8 <20 20 20 20 20 20 20 20>;
					rates-mcs =
					/bits/ 8 <4 63 63 63 63 63 63 63 63 63 63>;
					rates-ru =
					/bits/ 8 <4 20 20 20 20 20 20 20 20 20 20 20 20>,
					/bits/ 8 <1 25 25 25 25 25 25 25 25 25 25 25 25>,
					/bits/ 8 <1 32 32 32 32 32 32 32 32 32 32 32 32>,
					/bits/ 8 <1 38 38 38 38 38 38 38 38 38 38 38 38>;
					rates-eht =
					/bits/ 8 <4 20 20 20 20 20 20 20 20 20 20 20 20 20 20 20 20>,
					/bits/ 8 <1 25 25 25 25 25 25 25 25 25 25 25 25 25 25 25 25>,
					/bits/ 8 <1 32 32 32 32 32 32 32 32 32 32 32 32 32 32 32 32>,
					/bits/ 8 <1 38 38 38 38 38 38 38 38 38 38 38 38 38 38 38 38>,
					/bits/ 8 <1 42 42 42 42 42 42 42 42 42 42 42 42 42 42 42 42>,
					/bits/ 8 <2 20 20 20 20 20 20 20 20 20 20 20 20 20 20 20 20>,
					/bits/ 8 <1 32 32 32 32 32 32 32 32 32 32 32 32 32 32 32 32>,
					/bits/ 8 <2 38 38 38 38 38 38 38 38 38 38 38 38 38 38 38 38>,
					/bits/ 8 <3 42 42 42 42 42 42 42 42 42 42 42 42 42 42 42 42>;
					paths-cck = /bits/ 8 <63 63 63 63 63>;
					paths-ofdm = /bits/ 8 <20 14 10 8 6>;
					paths-ofdm-bf = /bits/ 8 <8 1 0 0>;
					paths-ru =
					/bits/ 8 <6 20 14 10 8 6 14 10 8 6 10 8 6 8 6 6>,
					/bits/ 8 <1 25 19 15 13 11 19 15 13 11 15 13 11 13 11 11>,
					/bits/ 8 <2 32 26 22 20 18 26 22 20 18 22 20 18 20 18 18>,
					/bits/ 8 <3 38 32 28 26 24 32 28 26 24 28 26 24 26 24 24>,
					/bits/ 8 <4 42 36 32 30 28 36 32 30 28 32 30 28 30 28 28>;
					paths-ru-bf =
					/bits/ 8 <6 20 8 1 0 0 14 7 2 0 10 5 2 8 4 6>,
					/bits/ 8 <1 25 13 6 1 0 19 12 7 3 15 10 7 13 9 11>,
					/bits/ 8 <2 32 20 13 8 4 26 19 14 10 22 17 14 20 16 18>,
					/bits/ 8 <3 38 26 19 14 10 32 25 20 16 28 23 20 26 22 24>,
					/bits/ 8 <4 42 30 23 18 14 36 29 24 20 32 27 24 30 26 28>;
				};
				r6 {
					channels = <101 101>;
					txs-delta = <0 0 0>;
					rates-cck = /bits/ 8 <63 63 63 63>;
					rates-ofdm = /bits/ 8 <20 20 20 20 20 20 20 20>;
					rates-mcs =
					/bits/ 8 <4 63 63 63 63 63 63 63 63 63 63>;
					rates-ru =
					/bits/ 8 <4 20 20 20 20 20 20 20 20 20 20 20 20>,
					/bits/ 8 <1 25 25 25 25 25 25 25 25 25 25 25 25>,
					/bits/ 8 <1 31 31 31 31 31 31 31 31 31 31 31 31>,
					/bits/ 8 <1 38 38 38 38 38 38 38 38 38 38 38 38>;
					rates-eht =
					/bits/ 8 <4 20 20 20 20 20 20 20 20 20 20 20 20 20 20 20 20>,
					/bits/ 8 <1 25 25 25 25 25 25 25 25 25 25 25 25 25 25 25 25>,
					/bits/ 8 <1 31 31 31 31 31 31 31 31 31 31 31 31 31 31 31 31>,
					/bits/ 8 <1 38 38 38 38 38 38 38 38 38 38 38 38 38 38 38 38>,
					/bits/ 8 <1 42 42 42 42 42 42 42 42 42 42 42 42 42 42 42 42>,
					/bits/ 8 <2 20 20 20 20 20 20 20 20 20 20 20 20 20 20 20 20>,
					/bits/ 8 <1 31 31 31 31 31 31 31 31 31 31 31 31 31 31 31 31>,
					/bits/ 8 <2 38 38 38 38 38 38 38 38 38 38 38 38 38 38 38 38>,
					/bits/ 8 <3 42 42 42 42 42 42 42 42 42 42 42 42 42 42 42 42>;
					paths-cck = /bits/ 8 <63 63 63 63 63>;
					paths-ofdm = /bits/ 8 <20 14 10 8 6>;
					paths-ofdm-bf = /bits/ 8 <8 1 0 0>;
					paths-ru =
					/bits/ 8 <6 20 14 10 8 6 14 10 8 6 10 8 6 8 6 6>,
					/bits/ 8 <1 25 19 15 13 11 19 15 13 11 15 13 11 13 11 11>,
					/bits/ 8 <2 31 25 21 19 17 25 21 19 17 21 19 17 19 17 17>,
					/bits/ 8 <3 38 32 28 26 24 32 28 26 24 28 26 24 26 24 24>,
					/bits/ 8 <4 42 36 32 30 28 36 32 30 28 32 30 28 30 28 28>;
					paths-ru-bf =
					/bits/ 8 <6 20 8 1 0 0 14 7 2 0 10 5 2 8 4 6>,
					/bits/ 8 <1 25 13 6 1 0 19 12 7 3 15 10 7 13 9 11>,
					/bits/ 8 <2 31 19 12 7 3 25 18 13 9 21 16 13 19 15 17>,
					/bits/ 8 <3 38 26 19 14 10 32 25 20 16 28 23 20 26 22 24>,
					/bits/ 8 <4 42 30 23 18 14 36 29 24 20 32 27 24 30 26 28>;
				};
				r7 {
					channels = <105 105>;
					txs-delta = <0 0 0>;
					rates-cck = /bits/ 8 <63 63 63 63>;
					rates-ofdm = /bits/ 8 <20 20 20 20 20 20 20 20>;
					rates-mcs =
					/bits/ 8 <4 63 63 63 63 63 63 63 63 63 63>;
					rates-ru =
					/bits/ 8 <4 20 20 20 20 20 20 20 20 20 20 20 20>,
					/bits/ 8 <1 24 24 24 24 24 24 24 24 24 24 24 24>,
					/bits/ 8 <1 31 31 31 31 31 31 31 31 31 31 31 31>,
					/bits/ 8 <1 38 38 38 38 38 38 38 38 38 38 38 38>;
					rates-eht =
					/bits/ 8 <4 20 20 20 20 20 20 20 20 20 20 20 20 20 20 20 20>,
					/bits/ 8 <1 24 24 24 24 24 24 24 24 24 24 24 24 24 24 24 24>,
					/bits/ 8 <1 31 31 31 31 31 31 31 31 31 31 31 31 31 31 31 31>,
					/bits/ 8 <1 38 38 38 38 38 38 38 38 38 38 38 38 38 38 38 38>,
					/bits/ 8 <1 42 42 42 42 42 42 42 42 42 42 42 42 42 42 42 42>,
					/bits/ 8 <2 20 20 20 20 20 20 20 20 20 20 20 20 20 20 20 20>,
					/bits/ 8 <1 31 31 31 31 31 31 31 31 31 31 31 31 31 31 31 31>,
					/bits/ 8 <2 38 38 38 38 38 38 38 38 38 38 38 38 38 38 38 38>,
					/bits/ 8 <3 42 42 42 42 42 42 42 42 42 42 42 42 42 42 42 42>;
					paths-cck = /bits/ 8 <63 63 63 63 63>;
					paths-ofdm = /bits/ 8 <20 14 10 8 6>;
					paths-ofdm-bf = /bits/ 8 <8 1 0 0>;
					paths-ru =
					/bits/ 8 <6 20 14 10 8 6 14 10 8 6 10 8 6 8 6 6>,
					/bits/ 8 <1 24 18 14 12 10 18 14 12 10 14 12 10 12 10 10>,
					/bits/ 8 <2 31 25 21 19 17 25 21 19 17 21 19 17 19 17 17>,
					/bits/ 8 <3 38 32 28 26 24 32 28 26 24 28 26 24 26 24 24>,
					/bits/ 8 <4 42 36 32 30 28 36 32 30 28 32 30 28 30 28 28>;
					paths-ru-bf =
					/bits/ 8 <6 20 8 1 0 0 14 7 2 0 10 5 2 8 4 6>,
					/bits/ 8 <1 24 12 5 0 0 18 11 6 2 14 9 6 12 8 10>,
					/bits/ 8 <2 31 19 12 7 3 25 18 13 9 21 16 13 19 15 17>,
					/bits/ 8 <3 38 26 19 14 10 32 25 20 16 28 23 20 26 22 24>,
					/bits/ 8 <4 42 30 23 18 14 36 29 24 20 32 27 24 30 26 28>;
				};
				r8 {
					channels = <109 109>;
					txs-delta = <0 0 0>;
					rates-cck = /bits/ 8 <63 63 63 63>;
					rates-ofdm = /bits/ 8 <20 20 20 20 20 20 20 20>;
					rates-mcs =
					/bits/ 8 <4 63 63 63 63 63 63 63 63 63 63>;
					rates-ru =
					/bits/ 8 <4 20 20 20 20 20 20 20 20 20 20 20 20>,
					/bits/ 8 <1 24 24 24 24 24 24 24 24 24 24 24 24>,
					/bits/ 8 <1 31 31 31 31 31 31 31 31 31 31 31 31>,
					/bits/ 8 <1 35 35 35 35 35 35 35 35 35 35 35 35>;
					rates-eht =
					/bits/ 8 <4 20 20 20 20 20 20 20 20 20 20 20 20 20 20 20 20>,
					/bits/ 8 <1 24 24 24 24 24 24 24 24 24 24 24 24 24 24 24 24>,
					/bits/ 8 <1 31 31 31 31 31 31 31 31 31 31 31 31 31 31 31 31>,
					/bits/ 8 <1 35 35 35 35 35 35 35 35 35 35 35 35 35 35 35 35>,
					/bits/ 8 <1 42 42 42 42 42 42 42 42 42 42 42 42 42 42 42 42>,
					/bits/ 8 <2 20 20 20 20 20 20 20 20 20 20 20 20 20 20 20 20>,
					/bits/ 8 <1 31 31 31 31 31 31 31 31 31 31 31 31 31 31 31 31>,
					/bits/ 8 <2 35 35 35 35 35 35 35 35 35 35 35 35 35 35 35 35>,
					/bits/ 8 <3 42 42 42 42 42 42 42 42 42 42 42 42 42 42 42 42>;
					paths-cck = /bits/ 8 <63 63 63 63 63>;
					paths-ofdm = /bits/ 8 <20 14 10 8 6>;
					paths-ofdm-bf = /bits/ 8 <8 1 0 0>;
					paths-ru =
					/bits/ 8 <6 20 14 10 8 6 14 10 8 6 10 8 6 8 6 6>,
					/bits/ 8 <1 24 18 14 12 10 18 14 12 10 14 12 10 12 10 10>,
					/bits/ 8 <2 31 25 21 19 17 25 21 19 17 21 19 17 19 17 17>,
					/bits/ 8 <3 35 29 25 23 21 29 25 23 21 25 23 21 23 21 21>,
					/bits/ 8 <4 42 36 32 30 28 36 32 30 28 32 30 28 30 28 28>;
					paths-ru-bf =
					/bits/ 8 <6 20 8 1 0 0 14 7 2 0 10 5 2 8 4 6>,
					/bits/ 8 <1 24 12 5 0 0 18 11 6 2 14 9 6 12 8 10>,
					/bits/ 8 <2 31 19 12 7 3 25 18 13 9 21 16 13 19 15 17>,
					/bits/ 8 <3 35 23 16 11 7 29 22 17 13 25 20 17 23 19 21>,
					/bits/ 8 <4 42 30 23 18 14 36 29 24 20 32 27 24 30 26 28>;
				};
				r9 {
					channels = <113 113>;
					txs-delta = <0 0 0>;
					rates-cck = /bits/ 8 <63 63 63 63>;
					rates-ofdm = /bits/ 8 <20 20 20 20 20 20 20 20>;
					rates-mcs =
					/bits/ 8 <4 63 63 63 63 63 63 63 63 63 63>;
					rates-ru =
					/bits/ 8 <4 20 20 20 20 20 20 20 20 20 20 20 20>,
					/bits/ 8 <1 25 25 25 25 25 25 25 25 25 25 25 25>,
					/bits/ 8 <1 31 31 31 31 31 31 31 31 31 31 31 31>,
					/bits/ 8 <1 35 35 35 35 35 35 35 35 35 35 35 35>;
					rates-eht =
					/bits/ 8 <4 20 20 20 20 20 20 20 20 20 20 20 20 20 20 20 20>,
					/bits/ 8 <1 25 25 25 25 25 25 25 25 25 25 25 25 25 25 25 25>,
					/bits/ 8 <1 31 31 31 31 31 31 31 31 31 31 31 31 31 31 31 31>,
					/bits/ 8 <1 35 35 35 35 35 35 35 35 35 35 35 35 35 35 35 35>,
					/bits/ 8 <1 42 42 42 42 42 42 42 42 42 42 42 42 42 42 42 42>,
					/bits/ 8 <2 20 20 20 20 20 20 20 20 20 20 20 20 20 20 20 20>,
					/bits/ 8 <1 31 31 31 31 31 31 31 31 31 31 31 31 31 31 31 31>,
					/bits/ 8 <2 35 35 35 35 35 35 35 35 35 35 35 35 35 35 35 35>,
					/bits/ 8 <3 42 42 42 42 42 42 42 42 42 42 42 42 42 42 42 42>;
					paths-cck = /bits/ 8 <63 63 63 63 63>;
					paths-ofdm = /bits/ 8 <20 14 10 8 6>;
					paths-ofdm-bf = /bits/ 8 <8 1 0 0>;
					paths-ru =
					/bits/ 8 <6 20 14 10 8 6 14 10 8 6 10 8 6 8 6 6>,
					/bits/ 8 <1 25 19 15 13 11 19 15 13 11 15 13 11 13 11 11>,
					/bits/ 8 <2 31 25 21 19 17 25 21 19 17 21 19 17 19 17 17>,
					/bits/ 8 <3 35 29 25 23 21 29 25 23 21 25 23 21 23 21 21>,
					/bits/ 8 <4 42 36 32 30 28 36 32 30 28 32 30 28 30 28 28>;
					paths-ru-bf =
					/bits/ 8 <6 20 8 1 0 0 14 7 2 0 10 5 2 8 4 6>,
					/bits/ 8 <1 25 13 6 1 0 19 12 7 3 15 10 7 13 9 11>,
					/bits/ 8 <2 31 19 12 7 3 25 18 13 9 21 16 13 19 15 17>,
					/bits/ 8 <3 35 23 16 11 7 29 22 17 13 25 20 17 23 19 21>,
					/bits/ 8 <4 42 30 23 18 14 36 29 24 20 32 27 24 30 26 28>;
				};
				r10 {
					channels = <117 121>;
					txs-delta = <0 0 0>;
					rates-cck = /bits/ 8 <63 63 63 63>;
					rates-ofdm = /bits/ 8 <21 21 21 21 21 21 21 21>;
					rates-mcs =
					/bits/ 8 <4 63 63 63 63 63 63 63 63 63 63>;
					rates-ru =
					/bits/ 8 <4 21 21 21 21 21 21 21 21 21 21 21 21>,
					/bits/ 8 <1 25 25 25 25 25 25 25 25 25 25 25 25>,
					/bits/ 8 <1 30 30 30 30 30 30 30 30 30 30 30 30>,
					/bits/ 8 <1 35 35 35 35 35 35 35 35 35 35 35 35>;
					rates-eht =
					/bits/ 8 <4 21 21 21 21 21 21 21 21 21 21 21 21 21 21 21 21>,
					/bits/ 8 <1 25 25 25 25 25 25 25 25 25 25 25 25 25 25 25 25>,
					/bits/ 8 <1 30 30 30 30 30 30 30 30 30 30 30 30 30 30 30 30>,
					/bits/ 8 <1 35 35 35 35 35 35 35 35 35 35 35 35 35 35 35 35>,
					/bits/ 8 <1 42 42 42 42 42 42 42 42 42 42 42 42 42 42 42 42>,
					/bits/ 8 <2 21 21 21 21 21 21 21 21 21 21 21 21 21 21 21 21>,
					/bits/ 8 <1 30 30 30 30 30 30 30 30 30 30 30 30 30 30 30 30>,
					/bits/ 8 <2 35 35 35 35 35 35 35 35 35 35 35 35 35 35 35 35>,
					/bits/ 8 <3 42 42 42 42 42 42 42 42 42 42 42 42 42 42 42 42>;
					paths-cck = /bits/ 8 <63 63 63 63 63>;
					paths-ofdm = /bits/ 8 <21 15 11 9 7>;
					paths-ofdm-bf = /bits/ 8 <9 2 0 0>;
					paths-ru =
					/bits/ 8 <6 21 15 11 9 7 15 11 9 7 11 9 7 9 7 7>,
					/bits/ 8 <1 25 19 15 13 11 19 15 13 11 15 13 11 13 11 11>,
					/bits/ 8 <2 30 24 20 18 16 24 20 18 16 20 18 16 18 16 16>,
					/bits/ 8 <3 35 29 25 23 21 29 25 23 21 25 23 21 23 21 21>,
					/bits/ 8 <4 42 36 32 30 28 36 32 30 28 32 30 28 30 28 28>;
					paths-ru-bf =
					/bits/ 8 <6 21 9 2 0 0 15 8 3 0 11 6 3 9 5 7>,
					/bits/ 8 <1 25 13 6 1 0 19 12 7 3 15 10 7 13 9 11>,
					/bits/ 8 <2 30 18 11 6 2 24 17 12 8 20 15 12 18 14 16>,
					/bits/ 8 <3 35 23 16 11 7 29 22 17 13 25 20 17 23 19 21>,
					/bits/ 8 <4 42 30 23 18 14 36 29 24 20 32 27 24 30 26 28>;
				};
				r11 {
					channels = <125 129>;
					txs-delta = <0 0 0>;
					rates-cck = /bits/ 8 <63 63 63 63>;
					rates-ofdm = /bits/ 8 <21 21 21 21 21 21 21 21>;
					rates-mcs =
					/bits/ 8 <4 63 63 63 63 63 63 63 63 63 63>;
					rates-ru =
					/bits/ 8 <4 21 21 21 21 21 21 21 21 21 21 21 21>,
					/bits/ 8 <1 25 25 25 25 25 25 25 25 25 25 25 25>,
					/bits/ 8 <1 30 30 30 30 30 30 30 30 30 30 30 30>,
					/bits/ 8 <1 35 35 35 35 35 35 35 35 35 35 35 35>;
					rates-eht =
					/bits/ 8 <4 21 21 21 21 21 21 21 21 21 21 21 21 21 21 21 21>,
					/bits/ 8 <1 25 25 25 25 25 25 25 25 25 25 25 25 25 25 25 25>,
					/bits/ 8 <1 30 30 30 30 30 30 30 30 30 30 30 30 30 30 30 30>,
					/bits/ 8 <1 35 35 35 35 35 35 35 35 35 35 35 35 35 35 35 35>,
					/bits/ 8 <1 40 40 40 40 40 40 40 40 40 40 40 40 40 40 40 40>,
					/bits/ 8 <2 21 21 21 21 21 21 21 21 21 21 21 21 21 21 21 21>,
					/bits/ 8 <1 30 30 30 30 30 30 30 30 30 30 30 30 30 30 30 30>,
					/bits/ 8 <2 35 35 35 35 35 35 35 35 35 35 35 35 35 35 35 35>,
					/bits/ 8 <3 40 40 40 40 40 40 40 40 40 40 40 40 40 40 40 40>;
					paths-cck = /bits/ 8 <63 63 63 63 63>;
					paths-ofdm = /bits/ 8 <21 15 11 9 7>;
					paths-ofdm-bf = /bits/ 8 <9 2 0 0>;
					paths-ru =
					/bits/ 8 <6 21 15 11 9 7 15 11 9 7 11 9 7 9 7 7>,
					/bits/ 8 <1 25 19 15 13 11 19 15 13 11 15 13 11 13 11 11>,
					/bits/ 8 <2 30 24 20 18 16 24 20 18 16 20 18 16 18 16 16>,
					/bits/ 8 <3 35 29 25 23 21 29 25 23 21 25 23 21 23 21 21>,
					/bits/ 8 <4 40 34 30 28 26 34 30 28 26 30 28 26 28 26 26>;
					paths-ru-bf =
					/bits/ 8 <6 21 9 2 0 0 15 8 3 0 11 6 3 9 5 7>,
					/bits/ 8 <1 25 13 6 1 0 19 12 7 3 15 10 7 13 9 11>,
					/bits/ 8 <2 30 18 11 6 2 24 17 12 8 20 15 12 18 14 16>,
					/bits/ 8 <3 35 23 16 11 7 29 22 17 13 25 20 17 23 19 21>,
					/bits/ 8 <4 40 28 21 16 12 34 27 22 18 30 25 22 28 24 26>;
				};
				r12 {
					channels = <133 137>;
					txs-delta = <0 0 0>;
					rates-cck = /bits/ 8 <63 63 63 63>;
					rates-ofdm = /bits/ 8 <21 21 21 21 21 21 21 21>;
					rates-mcs =
					/bits/ 8 <4 63 63 63 63 63 63 63 63 63 63>;
					rates-ru =
					/bits/ 8 <4 21 21 21 21 21 21 21 21 21 21 21 21>,
					/bits/ 8 <1 25 25 25 25 25 25 25 25 25 25 25 25>,
					/bits/ 8 <1 31 31 31 31 31 31 31 31 31 31 31 31>,
					/bits/ 8 <1 35 35 35 35 35 35 35 35 35 35 35 35>;
					rates-eht =
					/bits/ 8 <4 21 21 21 21 21 21 21 21 21 21 21 21 21 21 21 21>,
					/bits/ 8 <1 25 25 25 25 25 25 25 25 25 25 25 25 25 25 25 25>,
					/bits/ 8 <1 31 31 31 31 31 31 31 31 31 31 31 31 31 31 31 31>,
					/bits/ 8 <1 35 35 35 35 35 35 35 35 35 35 35 35 35 35 35 35>,
					/bits/ 8 <1 40 40 40 40 40 40 40 40 40 40 40 40 40 40 40 40>,
					/bits/ 8 <2 21 21 21 21 21 21 21 21 21 21 21 21 21 21 21 21>,
					/bits/ 8 <1 31 31 31 31 31 31 31 31 31 31 31 31 31 31 31 31>,
					/bits/ 8 <2 35 35 35 35 35 35 35 35 35 35 35 35 35 35 35 35>,
					/bits/ 8 <3 40 40 40 40 40 40 40 40 40 40 40 40 40 40 40 40>;
					paths-cck = /bits/ 8 <63 63 63 63 63>;
					paths-ofdm = /bits/ 8 <21 15 11 9 7>;
					paths-ofdm-bf = /bits/ 8 <9 2 0 0>;
					paths-ru =
					/bits/ 8 <6 21 15 11 9 7 15 11 9 7 11 9 7 9 7 7>,
					/bits/ 8 <1 25 19 15 13 11 19 15 13 11 15 13 11 13 11 11>,
					/bits/ 8 <2 31 25 21 19 17 25 21 19 17 21 19 17 19 17 17>,
					/bits/ 8 <3 35 29 25 23 21 29 25 23 21 25 23 21 23 21 21>,
					/bits/ 8 <4 40 34 30 28 26 34 30 28 26 30 28 26 28 26 26>;
					paths-ru-bf =
					/bits/ 8 <6 21 9 2 0 0 15 8 3 0 11 6 3 9 5 7>,
					/bits/ 8 <1 25 13 6 1 0 19 12 7 3 15 10 7 13 9 11>,
					/bits/ 8 <2 31 19 12 7 3 25 18 13 9 21 16 13 19 15 17>,
					/bits/ 8 <3 35 23 16 11 7 29 22 17 13 25 20 17 23 19 21>,
					/bits/ 8 <4 40 28 21 16 12 34 27 22 18 30 25 22 28 24 26>;
				};
				r13 {
					channels = <141 145>;
					txs-delta = <0 0 0>;
					rates-cck = /bits/ 8 <63 63 63 63>;
					rates-ofdm = /bits/ 8 <21 21 21 21 21 21 21 21>;
					rates-mcs =
					/bits/ 8 <4 63 63 63 63 63 63 63 63 63 63>;
					rates-ru =
					/bits/ 8 <4 21 21 21 21 21 21 21 21 21 21 21 21>,
					/bits/ 8 <1 25 25 25 25 25 25 25 25 25 25 25 25>,
					/bits/ 8 <1 31 31 31 31 31 31 31 31 31 31 31 31>,
					/bits/ 8 <1 36 36 36 36 36 36 36 36 36 36 36 36>;
					rates-eht =
					/bits/ 8 <4 21 21 21 21 21 21 21 21 21 21 21 21 21 21 21 21>,
					/bits/ 8 <1 25 25 25 25 25 25 25 25 25 25 25 25 25 25 25 25>,
					/bits/ 8 <1 31 31 31 31 31 31 31 31 31 31 31 31 31 31 31 31>,
					/bits/ 8 <1 36 36 36 36 36 36 36 36 36 36 36 36 36 36 36 36>,
					/bits/ 8 <1 40 40 40 40 40 40 40 40 40 40 40 40 40 40 40 40>,
					/bits/ 8 <2 21 21 21 21 21 21 21 21 21 21 21 21 21 21 21 21>,
					/bits/ 8 <1 31 31 31 31 31 31 31 31 31 31 31 31 31 31 31 31>,
					/bits/ 8 <2 36 36 36 36 36 36 36 36 36 36 36 36 36 36 36 36>,
					/bits/ 8 <3 40 40 40 40 40 40 40 40 40 40 40 40 40 40 40 40>;
					paths-cck = /bits/ 8 <63 63 63 63 63>;
					paths-ofdm = /bits/ 8 <21 15 11 9 7>;
					paths-ofdm-bf = /bits/ 8 <9 2 0 0>;
					paths-ru =
					/bits/ 8 <6 21 15 11 9 7 15 11 9 7 11 9 7 9 7 7>,
					/bits/ 8 <1 25 19 15 13 11 19 15 13 11 15 13 11 13 11 11>,
					/bits/ 8 <2 31 25 21 19 17 25 21 19 17 21 19 17 19 17 17>,
					/bits/ 8 <3 36 30 26 24 22 30 26 24 22 26 24 22 24 22 22>,
					/bits/ 8 <4 40 34 30 28 26 34 30 28 26 30 28 26 28 26 26>;
					paths-ru-bf =
					/bits/ 8 <6 21 9 2 0 0 15 8 3 0 11 6 3 9 5 7>,
					/bits/ 8 <1 25 13 6 1 0 19 12 7 3 15 10 7 13 9 11>,
					/bits/ 8 <2 31 19 12 7 3 25 18 13 9 21 16 13 19 15 17>,
					/bits/ 8 <3 36 24 17 12 8 30 23 18 14 26 21 18 24 20 22>,
					/bits/ 8 <4 40 28 21 16 12 34 27 22 18 30 25 22 28 24 26>;
				};
				r14 {
					channels = <149 153>;
					txs-delta = <0 0 0>;
					rates-cck = /bits/ 8 <63 63 63 63>;
					rates-ofdm = /bits/ 8 <20 20 20 20 20 20 20 20>;
					rates-mcs =
					/bits/ 8 <4 63 63 63 63 63 63 63 63 63 63>;
					rates-ru =
					/bits/ 8 <4 20 20 20 20 20 20 20 20 20 20 20 20>,
					/bits/ 8 <1 25 25 25 25 25 25 25 25 25 25 25 25>,
					/bits/ 8 <1 30 30 30 30 30 30 30 30 30 30 30 30>,
					/bits/ 8 <1 36 36 36 36 36 36 36 36 36 36 36 36>;
					rates-eht =
					/bits/ 8 <4 20 20 20 20 20 20 20 20 20 20 20 20 20 20 20 20>,
					/bits/ 8 <1 25 25 25 25 25 25 25 25 25 25 25 25 25 25 25 25>,
					/bits/ 8 <1 30 30 30 30 30 30 30 30 30 30 30 30 30 30 30 30>,
					/bits/ 8 <1 36 36 36 36 36 36 36 36 36 36 36 36 36 36 36 36>,
					/bits/ 8 <1 40 40 40 40 40 40 40 40 40 40 40 40 40 40 40 40>,
					/bits/ 8 <2 20 20 20 20 20 20 20 20 20 20 20 20 20 20 20 20>,
					/bits/ 8 <1 30 30 30 30 30 30 30 30 30 30 30 30 30 30 30 30>,
					/bits/ 8 <2 36 36 36 36 36 36 36 36 36 36 36 36 36 36 36 36>,
					/bits/ 8 <3 40 40 40 40 40 40 40 40 40 40 40 40 40 40 40 40>;
					paths-cck = /bits/ 8 <63 63 63 63 63>;
					paths-ofdm = /bits/ 8 <20 14 10 8 6>;
					paths-ofdm-bf = /bits/ 8 <8 1 0 0>;
					paths-ru =
					/bits/ 8 <6 20 14 10 8 6 14 10 8 6 10 8 6 8 6 6>,
					/bits/ 8 <1 25 19 15 13 11 19 15 13 11 15 13 11 13 11 11>,
					/bits/ 8 <2 30 24 20 18 16 24 20 18 16 20 18 16 18 16 16>,
					/bits/ 8 <3 36 30 26 24 22 30 26 24 22 26 24 22 24 22 22>,
					/bits/ 8 <4 40 34 30 28 26 34 30 28 26 30 28 26 28 26 26>;
					paths-ru-bf =
					/bits/ 8 <6 20 8 1 0 0 14 7 2 0 10 5 2 8 4 6>,
					/bits/ 8 <1 25 13 6 1 0 19 12 7 3 15 10 7 13 9 11>,
					/bits/ 8 <2 30 18 11 6 2 24 17 12 8 20 15 12 18 14 16>,
					/bits/ 8 <3 36 24 17 12 8 30 23 18 14 26 21 18 24 20 22>,
					/bits/ 8 <4 40 28 21 16 12 34 27 22 18 30 25 22 28 24 26>;
				};
				r15 {
					channels = <157 161>;
					txs-delta = <0 0 0>;
					rates-cck = /bits/ 8 <63 63 63 63>;
					rates-ofdm = /bits/ 8 <20 20 20 20 20 20 20 20>;
					rates-mcs =
					/bits/ 8 <4 63 63 63 63 63 63 63 63 63 63>;
					rates-ru =
					/bits/ 8 <4 20 20 20 20 20 20 20 20 20 20 20 20>,
					/bits/ 8 <1 25 25 25 25 25 25 25 25 25 25 25 25>,
					/bits/ 8 <1 30 30 30 30 30 30 30 30 30 30 30 30>,
					/bits/ 8 <1 36 36 36 36 36 36 36 36 36 36 36 36>;
					rates-eht =
					/bits/ 8 <4 20 20 20 20 20 20 20 20 20 20 20 20 20 20 20 20>,
					/bits/ 8 <1 25 25 25 25 25 25 25 25 25 25 25 25 25 25 25 25>,
					/bits/ 8 <1 30 30 30 30 30 30 30 30 30 30 30 30 30 30 30 30>,
					/bits/ 8 <1 36 36 36 36 36 36 36 36 36 36 36 36 36 36 36 36>,
					/bits/ 8 <1 41 41 41 41 41 41 41 41 41 41 41 41 41 41 41 41>,
					/bits/ 8 <2 20 20 20 20 20 20 20 20 20 20 20 20 20 20 20 20>,
					/bits/ 8 <1 30 30 30 30 30 30 30 30 30 30 30 30 30 30 30 30>,
					/bits/ 8 <2 36 36 36 36 36 36 36 36 36 36 36 36 36 36 36 36>,
					/bits/ 8 <3 41 41 41 41 41 41 41 41 41 41 41 41 41 41 41 41>;
					paths-cck = /bits/ 8 <63 63 63 63 63>;
					paths-ofdm = /bits/ 8 <20 14 10 8 6>;
					paths-ofdm-bf = /bits/ 8 <8 1 0 0>;
					paths-ru =
					/bits/ 8 <6 20 14 10 8 6 14 10 8 6 10 8 6 8 6 6>,
					/bits/ 8 <1 25 19 15 13 11 19 15 13 11 15 13 11 13 11 11>,
					/bits/ 8 <2 30 24 20 18 16 24 20 18 16 20 18 16 18 16 16>,
					/bits/ 8 <3 36 30 26 24 22 30 26 24 22 26 24 22 24 22 22>,
					/bits/ 8 <4 41 35 31 29 27 35 31 29 27 31 29 27 29 27 27>;
					paths-ru-bf =
					/bits/ 8 <6 20 8 1 0 0 14 7 2 0 10 5 2 8 4 6>,
					/bits/ 8 <1 25 13 6 1 0 19 12 7 3 15 10 7 13 9 11>,
					/bits/ 8 <2 30 18 11 6 2 24 17 12 8 20 15 12 18 14 16>,
					/bits/ 8 <3 36 24 17 12 8 30 23 18 14 26 21 18 24 20 22>,
					/bits/ 8 <4 41 29 22 17 13 35 28 23 19 31 26 23 29 25 27>;
				};
				r16 {
					channels = <165 169>;
					txs-delta = <0 0 0>;
					rates-cck = /bits/ 8 <63 63 63 63>;
					rates-ofdm = /bits/ 8 <20 20 20 20 20 20 20 20>;
					rates-mcs =
					/bits/ 8 <4 63 63 63 63 63 63 63 63 63 63>;
					rates-ru =
					/bits/ 8 <4 20 20 20 20 20 20 20 20 20 20 20 20>,
					/bits/ 8 <1 25 25 25 25 25 25 25 25 25 25 25 25>,
					/bits/ 8 <1 31 31 31 31 31 31 31 31 31 31 31 31>,
					/bits/ 8 <1 36 36 36 36 36 36 36 36 36 36 36 36>;
					rates-eht =
					/bits/ 8 <4 20 20 20 20 20 20 20 20 20 20 20 20 20 20 20 20>,
					/bits/ 8 <1 25 25 25 25 25 25 25 25 25 25 25 25 25 25 25 25>,
					/bits/ 8 <1 31 31 31 31 31 31 31 31 31 31 31 31 31 31 31 31>,
					/bits/ 8 <1 36 36 36 36 36 36 36 36 36 36 36 36 36 36 36 36>,
					/bits/ 8 <1 41 41 41 41 41 41 41 41 41 41 41 41 41 41 41 41>,
					/bits/ 8 <2 20 20 20 20 20 20 20 20 20 20 20 20 20 20 20 20>,
					/bits/ 8 <1 31 31 31 31 31 31 31 31 31 31 31 31 31 31 31 31>,
					/bits/ 8 <2 36 36 36 36 36 36 36 36 36 36 36 36 36 36 36 36>,
					/bits/ 8 <3 41 41 41 41 41 41 41 41 41 41 41 41 41 41 41 41>;
					paths-cck = /bits/ 8 <63 63 63 63 63>;
					paths-ofdm = /bits/ 8 <20 14 10 8 6>;
					paths-ofdm-bf = /bits/ 8 <8 1 0 0>;
					paths-ru =
					/bits/ 8 <6 20 14 10 8 6 14 10 8 6 10 8 6 8 6 6>,
					/bits/ 8 <1 25 19 15 13 11 19 15 13 11 15 13 11 13 11 11>,
					/bits/ 8 <2 31 25 21 19 17 25 21 19 17 21 19 17 19 17 17>,
					/bits/ 8 <3 36 30 26 24 22 30 26 24 22 26 24 22 24 22 22>,
					/bits/ 8 <4 41 35 31 29 27 35 31 29 27 31 29 27 29 27 27>;
					paths-ru-bf =
					/bits/ 8 <6 20 8 1 0 0 14 7 2 0 10 5 2 8 4 6>,
					/bits/ 8 <1 25 13 6 1 0 19 12 7 3 15 10 7 13 9 11>,
					/bits/ 8 <2 31 19 12 7 3 25 18 13 9 21 16 13 19 15 17>,
					/bits/ 8 <3 36 24 17 12 8 30 23 18 14 26 21 18 24 20 22>,
					/bits/ 8 <4 41 29 22 17 13 35 28 23 19 31 26 23 29 25 27>;
				};
				r17 {
					channels = <173 185>;
					txs-delta = <0 0 0>;
					rates-cck = /bits/ 8 <63 63 63 63>;
					rates-ofdm = /bits/ 8 <20 20 20 20 20 20 20 20>;
					rates-mcs =
					/bits/ 8 <4 63 63 63 63 63 63 63 63 63 63>;
					rates-ru =
					/bits/ 8 <4 20 20 20 20 20 20 20 20 20 20 20 20>,
					/bits/ 8 <1 25 25 25 25 25 25 25 25 25 25 25 25>,
					/bits/ 8 <1 31 31 31 31 31 31 31 31 31 31 31 31>,
					/bits/ 8 <1 37 37 37 37 37 37 37 37 37 37 37 37>;
					rates-eht =
					/bits/ 8 <4 20 20 20 20 20 20 20 20 20 20 20 20 20 20 20 20>,
					/bits/ 8 <1 25 25 25 25 25 25 25 25 25 25 25 25 25 25 25 25>,
					/bits/ 8 <1 31 31 31 31 31 31 31 31 31 31 31 31 31 31 31 31>,
					/bits/ 8 <1 37 37 37 37 37 37 37 37 37 37 37 37 37 37 37 37>,
					/bits/ 8 <1 41 41 41 41 41 41 41 41 41 41 41 41 41 41 41 41>,
					/bits/ 8 <2 20 20 20 20 20 20 20 20 20 20 20 20 20 20 20 20>,
					/bits/ 8 <1 31 31 31 31 31 31 31 31 31 31 31 31 31 31 31 31>,
					/bits/ 8 <2 37 37 37 37 37 37 37 37 37 37 37 37 37 37 37 37>,
					/bits/ 8 <3 41 41 41 41 41 41 41 41 41 41 41 41 41 41 41 41>;
					paths-cck = /bits/ 8 <63 63 63 63 63>;
					paths-ofdm = /bits/ 8 <20 14 10 8 6>;
					paths-ofdm-bf = /bits/ 8 <8 1 0 0>;
					paths-ru =
					/bits/ 8 <6 20 14 10 8 6 14 10 8 6 10 8 6 8 6 6>,
					/bits/ 8 <1 25 19 15 13 11 19 15 13 11 15 13 11 13 11 11>,
					/bits/ 8 <2 31 25 21 19 17 25 21 19 17 21 19 17 19 17 17>,
					/bits/ 8 <3 37 31 27 25 23 31 27 25 23 27 25 23 25 23 23>,
					/bits/ 8 <4 41 35 31 29 27 35 31 29 27 31 29 27 29 27 27>;
					paths-ru-bf =
					/bits/ 8 <6 20 8 1 0 0 14 7 2 0 10 5 2 8 4 6>,
					/bits/ 8 <1 25 13 6 1 0 19 12 7 3 15 10 7 13 9 11>,
					/bits/ 8 <2 31 19 12 7 3 25 18 13 9 21 16 13 19 15 17>,
					/bits/ 8 <3 37 25 18 13 9 31 24 19 15 27 22 19 25 21 23>,
					/bits/ 8 <4 41 29 22 17 13 35 28 23 19 31 26 23 29 25 27>;
				};
				r18 {
					channels = <189 189>;
					txs-delta = <0 0 0>;
					rates-cck = /bits/ 8 <63 63 63 63>;
					rates-ofdm = /bits/ 8 <21 21 21 21 21 21 21 21>;
					rates-mcs =
					/bits/ 8 <4 63 63 63 63 63 63 63 63 63 63>;
					rates-ru =
					/bits/ 8 <4 21 21 21 21 21 21 21 21 21 21 21 21>,
					/bits/ 8 <1 25 25 25 25 25 25 25 25 25 25 25 25>,
					/bits/ 8 <1 31 31 31 31 31 31 31 31 31 31 31 31>,
					/bits/ 8 <1 37 37 37 37 37 37 37 37 37 37 37 37>;
					rates-eht =
					/bits/ 8 <4 21 21 21 21 21 21 21 21 21 21 21 21 21 21 21 21>,
					/bits/ 8 <1 25 25 25 25 25 25 25 25 25 25 25 25 25 25 25 25>,
					/bits/ 8 <1 31 31 31 31 31 31 31 31 31 31 31 31 31 31 31 31>,
					/bits/ 8 <1 37 37 37 37 37 37 37 37 37 37 37 37 37 37 37 37>,
					/bits/ 8 <1 42 42 42 42 42 42 42 42 42 42 42 42 42 42 42 42>,
					/bits/ 8 <2 21 21 21 21 21 21 21 21 21 21 21 21 21 21 21 21>,
					/bits/ 8 <1 31 31 31 31 31 31 31 31 31 31 31 31 31 31 31 31>,
					/bits/ 8 <2 37 37 37 37 37 37 37 37 37 37 37 37 37 37 37 37>,
					/bits/ 8 <3 42 42 42 42 42 42 42 42 42 42 42 42 42 42 42 42>;
					paths-cck = /bits/ 8 <63 63 63 63 63>;
					paths-ofdm = /bits/ 8 <21 15 11 9 7>;
					paths-ofdm-bf = /bits/ 8 <9 2 0 0>;
					paths-ru =
					/bits/ 8 <6 21 15 11 9 7 15 11 9 7 11 9 7 9 7 7>,
					/bits/ 8 <1 25 19 15 13 11 19 15 13 11 15 13 11 13 11 11>,
					/bits/ 8 <2 31 25 21 19 17 25 21 19 17 21 19 17 19 17 17>,
					/bits/ 8 <3 37 31 27 25 23 31 27 25 23 27 25 23 25 23 23>,
					/bits/ 8 <4 42 36 32 30 28 36 32 30 28 32 30 28 30 28 28>;
					paths-ru-bf =
					/bits/ 8 <6 21 9 2 0 0 15 8 3 0 11 6 3 9 5 7>,
					/bits/ 8 <1 25 13 6 1 0 19 12 7 3 15 10 7 13 9 11>,
					/bits/ 8 <2 31 19 12 7 3 25 18 13 9 21 16 13 19 15 17>,
					/bits/ 8 <3 37 25 18 13 9 31 24 19 15 27 22 19 25 21 23>,
					/bits/ 8 <4 42 30 23 18 14 36 29 24 20 32 27 24 30 26 28>;
				};
				r19 {
					channels = <193 201>;
					txs-delta = <0 0 0>;
					rates-cck = /bits/ 8 <63 63 63 63>;
					rates-ofdm = /bits/ 8 <21 21 21 21 21 21 21 21>;
					rates-mcs =
					/bits/ 8 <4 63 63 63 63 63 63 63 63 63 63>;
					rates-ru =
					/bits/ 8 <4 21 21 21 21 21 21 21 21 21 21 21 21>,
					/bits/ 8 <1 26 26 26 26 26 26 26 26 26 26 26 26>,
					/bits/ 8 <1 31 31 31 31 31 31 31 31 31 31 31 31>,
					/bits/ 8 <1 37 37 37 37 37 37 37 37 37 37 37 37>;
					rates-eht =
					/bits/ 8 <4 21 21 21 21 21 21 21 21 21 21 21 21 21 21 21 21>,
					/bits/ 8 <1 26 26 26 26 26 26 26 26 26 26 26 26 26 26 26 26>,
					/bits/ 8 <1 31 31 31 31 31 31 31 31 31 31 31 31 31 31 31 31>,
					/bits/ 8 <1 37 37 37 37 37 37 37 37 37 37 37 37 37 37 37 37>,
					/bits/ 8 <1 42 42 42 42 42 42 42 42 42 42 42 42 42 42 42 42>,
					/bits/ 8 <2 21 21 21 21 21 21 21 21 21 21 21 21 21 21 21 21>,
					/bits/ 8 <1 31 31 31 31 31 31 31 31 31 31 31 31 31 31 31 31>,
					/bits/ 8 <2 37 37 37 37 37 37 37 37 37 37 37 37 37 37 37 37>,
					/bits/ 8 <3 42 42 42 42 42 42 42 42 42 42 42 42 42 42 42 42>;
					paths-cck = /bits/ 8 <63 63 63 63 63>;
					paths-ofdm = /bits/ 8 <21 15 11 9 7>;
					paths-ofdm-bf = /bits/ 8 <9 2 0 0>;
					paths-ru =
					/bits/ 8 <6 21 15 11 9 7 15 11 9 7 11 9 7 9 7 7>,
					/bits/ 8 <1 26 20 16 14 12 20 16 14 12 16 14 12 14 12 12>,
					/bits/ 8 <2 31 25 21 19 17 25 21 19 17 21 19 17 19 17 17>,
					/bits/ 8 <3 37 31 27 25 23 31 27 25 23 27 25 23 25 23 23>,
					/bits/ 8 <4 42 36 32 30 28 36 32 30 28 32 30 28 30 28 28>;
					paths-ru-bf =
					/bits/ 8 <6 21 9 2 0 0 15 8 3 0 11 6 3 9 5 7>,
					/bits/ 8 <1 26 14 7 2 0 20 13 8 4 16 11 8 14 10 12>,
					/bits/ 8 <2 31 19 12 7 3 25 18 13 9 21 16 13 19 15 17>,
					/bits/ 8 <3 37 25 18 13 9 31 24 19 15 27 22 19 25 21 23>,
					/bits/ 8 <4 42 30 23 18 14 36 29 24 20 32 27 24 30 26 28>;
				};
				r20 {
					channels = <205 205>;
					txs-delta = <0 0 0>;
					rates-cck = /bits/ 8 <63 63 63 63>;
					rates-ofdm = /bits/ 8 <21 21 21 21 21 21 21 21>;
					rates-mcs =
					/bits/ 8 <4 63 63 63 63 63 63 63 63 63 63>;
					rates-ru =
					/bits/ 8 <4 21 21 21 21 21 21 21 21 21 21 21 21>,
					/bits/ 8 <1 26 26 26 26 26 26 26 26 26 26 26 26>,
					/bits/ 8 <1 31 31 31 31 31 31 31 31 31 31 31 31>,
					/bits/ 8 <1 36 36 36 36 36 36 36 36 36 36 36 36>;
					rates-eht =
					/bits/ 8 <4 21 21 21 21 21 21 21 21 21 21 21 21 21 21 21 21>,
					/bits/ 8 <1 26 26 26 26 26 26 26 26 26 26 26 26 26 26 26 26>,
					/bits/ 8 <1 31 31 31 31 31 31 31 31 31 31 31 31 31 31 31 31>,
					/bits/ 8 <1 36 36 36 36 36 36 36 36 36 36 36 36 36 36 36 36>,
					/bits/ 8 <1 42 42 42 42 42 42 42 42 42 42 42 42 42 42 42 42>,
					/bits/ 8 <2 21 21 21 21 21 21 21 21 21 21 21 21 21 21 21 21>,
					/bits/ 8 <1 31 31 31 31 31 31 31 31 31 31 31 31 31 31 31 31>,
					/bits/ 8 <2 36 36 36 36 36 36 36 36 36 36 36 36 36 36 36 36>,
					/bits/ 8 <3 42 42 42 42 42 42 42 42 42 42 42 42 42 42 42 42>;
					paths-cck = /bits/ 8 <63 63 63 63 63>;
					paths-ofdm = /bits/ 8 <21 15 11 9 7>;
					paths-ofdm-bf = /bits/ 8 <9 2 0 0>;
					paths-ru =
					/bits/ 8 <6 21 15 11 9 7 15 11 9 7 11 9 7 9 7 7>,
					/bits/ 8 <1 26 20 16 14 12 20 16 14 12 16 14 12 14 12 12>,
					/bits/ 8 <2 31 25 21 19 17 25 21 19 17 21 19 17 19 17 17>,
					/bits/ 8 <3 36 30 26 24 22 30 26 24 22 26 24 22 24 22 22>,
					/bits/ 8 <4 42 36 32 30 28 36 32 30 28 32 30 28 30 28 28>;
					paths-ru-bf =
					/bits/ 8 <6 21 9 2 0 0 15 8 3 0 11 6 3 9 5 7>,
					/bits/ 8 <1 26 14 7 2 0 20 13 8 4 16 11 8 14 10 12>,
					/bits/ 8 <2 31 19 12 7 3 25 18 13 9 21 16 13 19 15 17>,
					/bits/ 8 <3 36 24 17 12 8 30 23 18 14 26 21 18 24 20 22>,
					/bits/ 8 <4 42 30 23 18 14 36 29 24 20 32 27 24 30 26 28>;
				};
				r21 {
					channels = <209 209>;
					txs-delta = <0 0 0>;
					rates-cck = /bits/ 8 <63 63 63 63>;
					rates-ofdm = /bits/ 8 <19 19 19 19 19 19 19 19>;
					rates-mcs =
					/bits/ 8 <4 63 63 63 63 63 63 63 63 63 63>;
					rates-ru =
					/bits/ 8 <4 19 19 19 19 19 19 19 19 19 19 19 19>,
					/bits/ 8 <1 24 24 24 24 24 24 24 24 24 24 24 24>,
					/bits/ 8 <1 31 31 31 31 31 31 31 31 31 31 31 31>,
					/bits/ 8 <1 36 36 36 36 36 36 36 36 36 36 36 36>;
					rates-eht =
					/bits/ 8 <4 19 19 19 19 19 19 19 19 19 19 19 19 19 19 19 19>,
					/bits/ 8 <1 24 24 24 24 24 24 24 24 24 24 24 24 24 24 24 24>,
					/bits/ 8 <1 31 31 31 31 31 31 31 31 31 31 31 31 31 31 31 31>,
					/bits/ 8 <1 36 36 36 36 36 36 36 36 36 36 36 36 36 36 36 36>,
					/bits/ 8 <1 42 42 42 42 42 42 42 42 42 42 42 42 42 42 42 42>,
					/bits/ 8 <2 19 19 19 19 19 19 19 19 19 19 19 19 19 19 19 19>,
					/bits/ 8 <1 31 31 31 31 31 31 31 31 31 31 31 31 31 31 31 31>,
					/bits/ 8 <2 36 36 36 36 36 36 36 36 36 36 36 36 36 36 36 36>,
					/bits/ 8 <3 42 42 42 42 42 42 42 42 42 42 42 42 42 42 42 42>;
					paths-cck = /bits/ 8 <63 63 63 63 63>;
					paths-ofdm = /bits/ 8 <19 13 9 7 5>;
					paths-ofdm-bf = /bits/ 8 <7 0 0 0>;
					paths-ru =
					/bits/ 8 <6 19 13 9 7 5 13 9 7 5 9 7 5 7 5 5>,
					/bits/ 8 <1 24 18 14 12 10 18 14 12 10 14 12 10 12 10 10>,
					/bits/ 8 <2 31 25 21 19 17 25 21 19 17 21 19 17 19 17 17>,
					/bits/ 8 <3 36 30 26 24 22 30 26 24 22 26 24 22 24 22 22>,
					/bits/ 8 <4 42 36 32 30 28 36 32 30 28 32 30 28 30 28 28>;
					paths-ru-bf =
					/bits/ 8 <6 19 7 0 0 0 13 6 1 0 9 4 1 7 3 5>,
					/bits/ 8 <1 24 12 5 0 0 18 11 6 2 14 9 6 12 8 10>,
					/bits/ 8 <2 31 19 12 7 3 25 18 13 9 21 16 13 19 15 17>,
					/bits/ 8 <3 36 24 17 12 8 30 23 18 14 26 21 18 24 20 22>,
					/bits/ 8 <4 42 30 23 18 14 36 29 24 20 32 27 24 30 26 28>;
				};
				r22 {
					channels = <213 221>;
					txs-delta = <0 0 0>;
					rates-cck = /bits/ 8 <63 63 63 63>;
					rates-ofdm = /bits/ 8 <19 19 19 19 19 19 19 19>;
					rates-mcs =
					/bits/ 8 <4 63 63 63 63 63 63 63 63 63 63>;
					rates-ru =
					/bits/ 8 <4 19 19 19 19 19 19 19 19 19 19 19 19>,
					/bits/ 8 <1 24 24 24 24 24 24 24 24 24 24 24 24>,
					/bits/ 8 <1 30 30 30 30 30 30 30 30 30 30 30 30>,
					/bits/ 8 <1 36 36 36 36 36 36 36 36 36 36 36 36>;
					rates-eht =
					/bits/ 8 <4 19 19 19 19 19 19 19 19 19 19 19 19 19 19 19 19>,
					/bits/ 8 <1 24 24 24 24 24 24 24 24 24 24 24 24 24 24 24 24>,
					/bits/ 8 <1 30 30 30 30 30 30 30 30 30 30 30 30 30 30 30 30>,
					/bits/ 8 <1 36 36 36 36 36 36 36 36 36 36 36 36 36 36 36 36>,
					/bits/ 8 <1 42 42 42 42 42 42 42 42 42 42 42 42 42 42 42 42>,
					/bits/ 8 <2 19 19 19 19 19 19 19 19 19 19 19 19 19 19 19 19>,
					/bits/ 8 <1 30 30 30 30 30 30 30 30 30 30 30 30 30 30 30 30>,
					/bits/ 8 <2 36 36 36 36 36 36 36 36 36 36 36 36 36 36 36 36>,
					/bits/ 8 <3 42 42 42 42 42 42 42 42 42 42 42 42 42 42 42 42>;
					paths-cck = /bits/ 8 <63 63 63 63 63>;
					paths-ofdm = /bits/ 8 <19 13 9 7 5>;
					paths-ofdm-bf = /bits/ 8 <7 0 0 0>;
					paths-ru =
					/bits/ 8 <6 19 13 9 7 5 13 9 7 5 9 7 5 7 5 5>,
					/bits/ 8 <1 24 18 14 12 10 18 14 12 10 14 12 10 12 10 10>,
					/bits/ 8 <2 30 24 20 18 16 24 20 18 16 20 18 16 18 16 16>,
					/bits/ 8 <3 36 30 26 24 22 30 26 24 22 26 24 22 24 22 22>,
					/bits/ 8 <4 42 36 32 30 28 36 32 30 28 32 30 28 30 28 28>;
					paths-ru-bf =
					/bits/ 8 <6 19 7 0 0 0 13 6 1 0 9 4 1 7 3 5>,
					/bits/ 8 <1 24 12 5 0 0 18 11 6 2 14 9 6 12 8 10>,
					/bits/ 8 <2 30 18 11 6 2 24 17 12 8 20 15 12 18 14 16>,
					/bits/ 8 <3 36 24 17 12 8 30 23 18 14 26 21 18 24 20 22>,
					/bits/ 8 <4 42 30 23 18 14 36 29 24 20 32 27 24 30 26 28>;
				};
				r23 {
					channels = <225 225>;
					txs-delta = <0 0 0>;
					rates-cck = /bits/ 8 <63 63 63 63>;
					rates-ofdm = /bits/ 8 <19 19 19 19 19 19 19 19>;
					rates-mcs =
					/bits/ 8 <4 63 63 63 63 63 63 63 63 63 63>;
					rates-ru =
					/bits/ 8 <4 19 19 19 19 19 19 19 19 19 19 19 19>,
					/bits/ 8 <1 26 26 26 26 26 26 26 26 26 26 26 26>,
					/bits/ 8 <1 30 30 30 30 30 30 30 30 30 30 30 30>,
					/bits/ 8 <1 36 36 36 36 36 36 36 36 36 36 36 36>;
					rates-eht =
					/bits/ 8 <4 19 19 19 19 19 19 19 19 19 19 19 19 19 19 19 19>,
					/bits/ 8 <1 26 26 26 26 26 26 26 26 26 26 26 26 26 26 26 26>,
					/bits/ 8 <1 30 30 30 30 30 30 30 30 30 30 30 30 30 30 30 30>,
					/bits/ 8 <1 36 36 36 36 36 36 36 36 36 36 36 36 36 36 36 36>,
					/bits/ 8 <1 42 42 42 42 42 42 42 42 42 42 42 42 42 42 42 42>,
					/bits/ 8 <2 19 19 19 19 19 19 19 19 19 19 19 19 19 19 19 19>,
					/bits/ 8 <1 30 30 30 30 30 30 30 30 30 30 30 30 30 30 30 30>,
					/bits/ 8 <2 36 36 36 36 36 36 36 36 36 36 36 36 36 36 36 36>,
					/bits/ 8 <3 42 42 42 42 42 42 42 42 42 42 42 42 42 42 42 42>;
					paths-cck = /bits/ 8 <63 63 63 63 63>;
					paths-ofdm = /bits/ 8 <19 13 9 7 5>;
					paths-ofdm-bf = /bits/ 8 <7 0 0 0>;
					paths-ru =
					/bits/ 8 <6 19 13 9 7 5 13 9 7 5 9 7 5 7 5 5>,
					/bits/ 8 <1 26 20 16 14 12 20 16 14 12 16 14 12 14 12 12>,
					/bits/ 8 <2 30 24 20 18 16 24 20 18 16 20 18 16 18 16 16>,
					/bits/ 8 <3 36 30 26 24 22 30 26 24 22 26 24 22 24 22 22>,
					/bits/ 8 <4 42 36 32 30 28 36 32 30 28 32 30 28 30 28 28>;
					paths-ru-bf =
					/bits/ 8 <6 19 7 0 0 0 13 6 1 0 9 4 1 7 3 5>,
					/bits/ 8 <1 26 14 7 2 0 20 13 8 4 16 11 8 14 10 12>,
					/bits/ 8 <2 30 18 11 6 2 24 17 12 8 20 15 12 18 14 16>,
					/bits/ 8 <3 36 24 17 12 8 30 23 18 14 26 21 18 24 20 22>,
					/bits/ 8 <4 42 30 23 18 14 36 29 24 20 32 27 24 30 26 28>;
				};
				r24 {
					channels = <229 233>;
					txs-delta = <0 0 0>;
					rates-cck = /bits/ 8 <63 63 63 63>;
					rates-ofdm = /bits/ 8 <22 22 22 22 22 22 22 22>;
					rates-mcs =
					/bits/ 8 <4 63 63 63 63 63 63 63 63 63 63>;
					rates-ru =
					/bits/ 8 <4 22 22 22 22 22 22 22 22 22 22 22 22>,
					/bits/ 8 <1 26 26 26 26 26 26 26 26 26 26 26 26>,
					/bits/ 8 <1 30 30 30 30 30 30 30 30 30 30 30 30>,
					/bits/ 8 <1 36 36 36 36 36 36 36 36 36 36 36 36>;
					rates-eht =
					/bits/ 8 <4 22 22 22 22 22 22 22 22 22 22 22 22 22 22 22 22>,
					/bits/ 8 <1 26 26 26 26 26 26 26 26 26 26 26 26 26 26 26 26>,
					/bits/ 8 <1 30 30 30 30 30 30 30 30 30 30 30 30 30 30 30 30>,
					/bits/ 8 <1 36 36 36 36 36 36 36 36 36 36 36 36 36 36 36 36>,
					/bits/ 8 <1 42 42 42 42 42 42 42 42 42 42 42 42 42 42 42 42>,
					/bits/ 8 <2 22 22 22 22 22 22 22 22 22 22 22 22 22 22 22 22>,
					/bits/ 8 <1 30 30 30 30 30 30 30 30 30 30 30 30 30 30 30 30>,
					/bits/ 8 <2 36 36 36 36 36 36 36 36 36 36 36 36 36 36 36 36>,
					/bits/ 8 <3 42 42 42 42 42 42 42 42 42 42 42 42 42 42 42 42>;
					paths-cck = /bits/ 8 <63 63 63 63 63>;
					paths-ofdm = /bits/ 8 <22 16 12 10 8>;
					paths-ofdm-bf = /bits/ 8 <10 3 0 0>;
					paths-ru =
					/bits/ 8 <6 22 16 12 10 8 16 12 10 8 12 10 8 10 8 8>,
					/bits/ 8 <1 26 20 16 14 12 20 16 14 12 16 14 12 14 12 12>,
					/bits/ 8 <2 30 24 20 18 16 24 20 18 16 20 18 16 18 16 16>,
					/bits/ 8 <3 36 30 26 24 22 30 26 24 22 26 24 22 24 22 22>,
					/bits/ 8 <4 42 36 32 30 28 36 32 30 28 32 30 28 30 28 28>;
					paths-ru-bf =
					/bits/ 8 <6 22 10 3 0 0 16 9 4 0 12 7 4 10 6 8>,
					/bits/ 8 <1 26 14 7 2 0 20 13 8 4 16 11 8 14 10 12>,
					/bits/ 8 <2 30 18 11 6 2 24 17 12 8 20 15 12 18 14 16>,
					/bits/ 8 <3 36 24 17 12 8 30 23 18 14 26 21 18 24 20 22>,
					/bits/ 8 <4 42 30 23 18 14 36 29 24 20 32 27 24 30 26 28>;
				};
			};
		};
	};
};
